AUTOSAR XML (schema 4-3-0)
package /CAN2/ISignalGroup
  10 x i signal group:
    CAN2_SG_FD2_C1000_0: i-signal=[CAN2_VCUVehAcclLimit, CAN2_VCUVehSpdlimit], system-signal-group=CAN2_SG_FD2_C1000_0
    CAN2_SG_CGW_FD2_C1000_0: i-signal=[CAN2_ACMODESta, CAN2_LBIBatWarn, CAN2_LBIPressIndi, CAN2_LBISensorFail, CAN2_LBIWheelPress, CAN2_LBIWheelTemp, CAN2_LBIWheelTmpIndi, CAN2_LBOBatWarn, CAN2_LBOPressIndi, CAN2_LBOSensorFail, CAN2_LBOWheelPress, CAN2_LBOWheelTemp, CAN2_LBOWheelTmpIndi, CAN2_LFBatWarn, CAN2_LFPressIndi, CAN2_LFSensorFail, CAN2_LFWheelPress, CAN2_LFWheelTemp, CAN2_LFWheelTmpIndi, CAN2_RBIBatWarn, CAN2_RBIPressIndi, CAN2_RBISensorFail, CAN2_RBIWheelPress, CAN2_RBIWheelTmpIndi, CAN2_RBOBatWarn, CAN2_RBOPressIndi, CAN2_RBOSensorFail, CAN2_RBOWheelPress, CAN2_RBOWheelTemp, CAN2_RBOWheelTmpIndi, CAN2_RFBatWarn, CAN2_RFPressIndi, CAN2_RFSensorFail, CAN2_RFWheelPress, CAN2_RFWheelTemp, CAN2_RFWheelTmpIndi, CAN2_THCM_Faultlv_Sta, CAN2_TPMSWarnIndi], system-signal-group=CAN2_SG_CGW_FD2_C1000_0
    CAN2_SG_FD2_C10_0: i-signal=[CAN2_ActDriveMode, CAN2_CeTraxSysReady, CAN2_CreeperSta, CAN2_EBrakeTorqLow, CAN2_EMotorOverSpd, CAN2_EMotorPerformance, CAN2_EMotorSpd, CAN2_EVECU1MSGCS, CAN2_EVECU1MSGCnt, CAN2_RecuperHighSta, CAN2_TUpASta, CAN2_VehActDriveDirect, CAN2_WheelSlipdet], system-signal-group=CAN2_SG_FD2_C10_0
    CAN2_SG_FD2_C200_0: i-signal=[CAN2_CACPresWarn, CAN2_FDC_VCU_VCUDRM_Sta, CAN2_SysPowerMode], system-signal-group=CAN2_SG_FD2_C200_0
    CAN2_SG_FD2_C500_0: i-signal=[CAN2_IGNKeySta, CAN2_VCU_VehicleSpd, CAN2_VSPFunc], system-signal-group=CAN2_SG_FD2_C500_0
    CAN2_SG_FD2_C50_0: i-signal=[CAN2_EVEHCMSGCS, CAN2_EVEHCMSGCnt, CAN2_EVSysRls, CAN2_ElecSysRdy, CAN2_ExtAccLimReq, CAN2_ExtDischgReq, CAN2_ExtDriveMReq, CAN2_ExtWorkshopMReq, CAN2_RecuperLimOrReq], system-signal-group=CAN2_SG_FD2_C50_0
    CAN2_SG_FD2_CE100_0: i-signal=[CAN2_FDC_BCM_BSD_Buzzer_Cmd, CAN2_FDC_BCM_Brake_Cmd, CAN2_FDC_BCM_CallBell_Cmd, CAN2_FDC_BCM_DVRSignalL_Cmd, CAN2_FDC_BCM_DVRSignalR_Cmd, CAN2_FDC_BCM_EmExitSW_Sta, CAN2_FDC_BCM_EmSV_Cmd, CAN2_FDC_BCM_FDCloseSV_Cmd, CAN2_FDC_BCM_FDOpenSV_Cmd, CAN2_FDC_BCM_FDoor_Sta, CAN2_FDC_BCM_FRoomLpSet_Sta, CAN2_FDC_BCM_HBeam_Cmd, CAN2_FDC_BCM_HazardSW_Sta, CAN2_FDC_BCM_HelpIND_Cmd, CAN2_FDC_BCM_InnerBuzzerMode_Sta, CAN2_FDC_BCM_InnerBuzzer_Cmd, CAN2_FDC_BCM_InnerCallBell_Cmd, CAN2_FDC_BCM_LBSDR_Cmd, CAN2_FDC_BCM_LBSDY_Cmd, CAN2_FDC_BCM_LBeam_Cmd, CAN2_FDC_BCM_LDRL_Cmd, CAN2_FDC_BCM_LTurnLp_Cmd, CAN2_FDC_BCM_LTurnSW_Sta, CAN2_FDC_BCM_MDCloseSV_Cmd, CAN2_FDC_BCM_MDOpenSV_Cmd, CAN2_FDC_BCM_MDoor_Sta, CAN2_FDC_BCM_MRoomLpSet_Sta, CAN2_FDC_BCM_OutDoorOpenSW_Sta, CAN2_FDC_BCM_PLamp_Cmd, CAN2_FDC_BCM_RBSDR_Cmd, CAN2_FDC_BCM_RBSDY_Cmd, CAN2_FDC_BCM_RDRL_Cmd, CAN2_FDC_BCM_RDoor_Sta, CAN2_FDC_BCM_RFLamp_Cmd, CAN2_FDC_BCM_RGear_Sta, CAN2_FDC_BCM_RRoomLpSet_Sta, CAN2_FDC_BCM_RTurnLp_Cmd, CAN2_FDC_BCM_RTurnSW_Sta, CAN2_FDC_BCM_RoomLpAmbSet_Sta, CAN2_FDC_BCM_RoomLpAmb_Cmd, CAN2_FDC_BCM_RoomLpSet_Sta, CAN2_FDC_BCM_SLTLp_Cmd, CAN2_FDC_BCM_SMKL_Cmd, CAN2_FDC_BCM_SMKR_Cmd, CAN2_FDC_BCM_SRTLp_Cmd, CAN2_FDC_BCM_STOPBALL_Cmd, CAN2_FDC_BCM_Stop_IND_Cmd, CAN2_FDC_BCM_TurnBuzzerEN_Sta, CAN2_FDC_BCM_TurnLpPattern_Sta, CAN2_FDC_BCM_Washer_Cmd, CAN2_FDC_BCM_WiperH_Cmd, CAN2_FDC_BCM_WiperL_Cmd], system-signal-group=CAN2_SG_FD2_CE100_0
    CAN2_SG_GW2_C100_0: i-signal=[CAN2_CACTempWarn, CAN2_DACStatus, CAN2_GearFlashInd, CAN2_LVBattLow, CAN2_PweLmtInd, CAN2_VCUWarnInd, CAN2_VCUnoPBInd], system-signal-group=CAN2_SG_GW2_C100_0
    CAN2_SG_CGW_GW2_C100_0: i-signal=[CAN2_ABSFullyOper, CAN2_ACTempSetSta, CAN2_ASC1KneelingInfo, CAN2_ASRBrakeCtrlAtc, CAN2_ASREngCtrlAtc, CAN2_AirPressureRC1, CAN2_B2THVRlySta, CAN2_B2VBI1BattType, CAN2_B2VBI1RateCap, CAN2_B2VBI1RateHVolt, CAN2_B2VBI1RatePower, CAN2_B2VChgMode, CAN2_B2VChgSta, CAN2_B2VDCChgConnSta, CAN2_B2VFaultCode, CAN2_B2VPChrgConnSta, CAN2_B2VSOC, CAN2_B2VSOH, CAN2_DCDC_En_Sta, CAN2_EBSAmWarnLampSta, CAN2_EBSBrakeSw, CAN2_EBSRedWarnLampSta, CAN2_ECASAWarmLampSta, CAN2_EHPS_ErrLv_Sta, CAN2_MCUFailGrade, CAN2_ParkBrakeSW, CAN2_TransReqGear, CAN2_VDCBrakeLightReq, CAN2_WhlSpeed_FL, CAN2_WhlSpeed_FR, CAN2_WhlSpeed_RL, CAN2_WhlSpeed_RR, CAN2_ZFR_CHASSIS_LiningWearFL_Sta, CAN2_ZFR_CHASSIS_LiningWearFR_Sta, CAN2_ZRR_CHASSIS_LiningWearRL_Sta, CAN2_ZRR_CHASSIS_LiningWearRR_Sta], system-signal-group=CAN2_SG_CGW_GW2_C100_0
    CAN2_SG_IVI_C100_0: i-signal=[CAN2_IVI_ACCoolTempSetdownReq_Cmd, CAN2_IVI_ACCoolTempSetupReq_Cmd, CAN2_IVI_ACFanSpdReq_Cmd, CAN2_IVI_ACHeatTempSetDownReq_Cmd, CAN2_IVI_ACHeatTempSetUPReq_Cmd, CAN2_IVI_ACMODEReq_Cmd, CAN2_IVI_ACOutCycleReq_Cmd, CAN2_IVI_ACPwrReq_Cmd, CAN2_IVI_ACRemoteReq_Cmd, CAN2_IVI_ACTempSet_Cmd], system-signal-group=CAN2_SG_IVI_C100_0
package /CAN2/Cluster
  can cluster CAN2: baudrate=500, can-fd-baudrate=2000
    can physical channel CAN2: comm-connectors=ConnCAN2
      frame CAN2_DiagFuncReqFT: id 0x7D0, frame-length=8, can-addressing-mode=STANDARD, can-fd-frame-support=false, can-frame-rx-behavior=CAN-20, can-frame-tx-behavior=CAN-20
        n pdu CAN2_DiagFuncReqFT: length=8
      frame CAN2_DiagPhysReqToCMS_L: id 0x6E2, frame-length=64, can-addressing-mode=STANDARD, can-fd-frame-support=true, can-frame-rx-behavior=CAN-FD, can-frame-tx-behavior=CAN-FD
        n pdu CAN2_DiagPhysReqToCMS_L: length=8
      frame CAN2_DiagPhysReqToCMS_R: id 0x6E3, frame-length=64, can-addressing-mode=STANDARD, can-fd-frame-support=true, can-frame-rx-behavior=CAN-FD, can-frame-tx-behavior=CAN-FD
        n pdu CAN2_DiagPhysReqToCMS_R: length=8
      frame CAN2_DiagPhysReqToIVI: id 0x6A0, frame-length=64, can-addressing-mode=STANDARD, can-fd-frame-support=true, can-frame-rx-behavior=CAN-FD, can-frame-tx-behavior=CAN-FD
        n pdu CAN2_DiagPhysReqToIVI: length=8
      frame CAN2_DiagPhysReqToIVI_F: id 0x6E0, frame-length=64, can-addressing-mode=STANDARD, can-fd-frame-support=true, can-frame-rx-behavior=CAN-FD, can-frame-tx-behavior=CAN-FD
        n pdu CAN2_DiagPhysReqToIVI_F: length=8
      frame CAN2_DiagPhysReqToIVI_M: id 0x6E1, frame-length=64, can-addressing-mode=STANDARD, can-fd-frame-support=true, can-frame-rx-behavior=CAN-FD, can-frame-tx-behavior=CAN-FD
        n pdu CAN2_DiagPhysReqToIVI_M: length=8
      frame CAN2_DiagPhysReqToMETER: id 0x682, frame-length=64, can-addressing-mode=STANDARD, can-fd-frame-support=true, can-frame-rx-behavior=CAN-FD, can-frame-tx-behavior=CAN-FD
        n pdu CAN2_DiagPhysReqToMETER: length=8
      frame CAN2_DiagRespFromCMS_L: id 0x662, frame-length=64, can-addressing-mode=STANDARD, can-fd-frame-support=true, can-frame-rx-behavior=CAN-FD, can-frame-tx-behavior=CAN-FD
        n pdu CAN2_DiagRespFromCMS_L: length=8
      frame CAN2_DiagRespFromCMS_R: id 0x663, frame-length=64, can-addressing-mode=STANDARD, can-fd-frame-support=true, can-frame-rx-behavior=CAN-FD, can-frame-tx-behavior=CAN-FD
        n pdu CAN2_DiagRespFromCMS_R: length=8
      frame CAN2_DiagRespFromIVI: id 0x620, frame-length=64, can-addressing-mode=STANDARD, can-fd-frame-support=true, can-frame-rx-behavior=CAN-FD, can-frame-tx-behavior=CAN-FD
        n pdu CAN2_DiagRespFromIVI: length=8
      frame CAN2_DiagRespFromIVI_F: id 0x660, frame-length=64, can-addressing-mode=STANDARD, can-fd-frame-support=true, can-frame-rx-behavior=CAN-FD, can-frame-tx-behavior=CAN-FD
        n pdu CAN2_DiagRespFromIVI_F: length=8
      frame CAN2_DiagRespFromIVI_M: id 0x661, frame-length=64, can-addressing-mode=STANDARD, can-fd-frame-support=true, can-frame-rx-behavior=CAN-FD, can-frame-tx-behavior=CAN-FD
        n pdu CAN2_DiagRespFromIVI_M: length=8
      frame CAN2_DiagRespFromMETER: id 0x602, frame-length=64, can-addressing-mode=STANDARD, can-fd-frame-support=true, can-frame-rx-behavior=CAN-FD, can-frame-tx-behavior=CAN-FD
        n pdu CAN2_DiagRespFromMETER: length=8
      frame CAN2_FD2_C1000_0: id 0x20E, frame-length=64, can-addressing-mode=STANDARD, can-fd-frame-support=true, can-frame-rx-behavior=CAN-FD, can-frame-tx-behavior=CAN-FD
        pdu CAN2_FD2_C1000_0: length=64, minimum-delay=0.0, transmission-mode-true-timing=cyclic-timing=time-period=1, unused-bit-pattern=0
          mapping CAN2_SG_FD2_C1000_0: i-signal-group=CAN2_SG_FD2_C1000_0, start-position=0, transfer-property=PENDING
          mapping CAN2_SG_CGW_FD2_C1000_0: i-signal-group=CAN2_SG_CGW_FD2_C1000_0, start-position=0, transfer-property=PENDING
          signal CAN2_ACMODESta: start 29, 2 bit, big-endian, i-signal-type=PRIMITIVE, init-value=constant-reference=Init_CAN2_ACMODESta, base-type=uint8, implementation-data-type=uint8, transfer-property=PENDING
          signal CAN2_LBIBatWarn: start 48, 1 bit, big-endian, i-signal-type=PRIMITIVE, init-value=constant-reference=Init_CAN2_LBIBatWarn, base-type=uint8, implementation-data-type=uint8, transfer-property=PENDING
          signal CAN2_LBIPressIndi: start 23, 2 bit, big-endian, i-signal-type=PRIMITIVE, init-value=constant-reference=Init_CAN2_LBIPressIndi, base-type=uint8, implementation-data-type=uint8, transfer-property=PENDING
          signal CAN2_LBISensorFail: start 24, 1 bit, big-endian, i-signal-type=PRIMITIVE, init-value=constant-reference=Init_CAN2_LBISensorFail, base-type=uint8, implementation-data-type=uint8, transfer-property=PENDING
          signal CAN2_LBIWheelPress: start 95, 8 bit, big-endian, i-signal-type=PRIMITIVE, init-value=constant-reference=Init_CAN2_LBIWheelPress, base-type=uint8, implementation-data-type=uint8, transfer-property=PENDING
          signal CAN2_LBIWheelTemp: start 39, 8 bit, big-endian, i-signal-type=PRIMITIVE, init-value=constant-reference=Init_CAN2_LBIWheelTemp, base-type=uint8, implementation-data-type=uint8, transfer-property=PENDING
          signal CAN2_LBIWheelTmpIndi: start 41, 1 bit, big-endian, i-signal-type=PRIMITIVE, init-value=constant-reference=Init_CAN2_LBIWheelTmpIndi, base-type=uint8, implementation-data-type=uint8, transfer-property=PENDING
          signal CAN2_LBOBatWarn: start 85, 1 bit, big-endian, i-signal-type=PRIMITIVE, init-value=constant-reference=Init_CAN2_LBOBatWarn, base-type=uint8, implementation-data-type=uint8, transfer-property=PENDING
          signal CAN2_LBOPressIndi: start 31, 2 bit, big-endian, i-signal-type=PRIMITIVE, init-value=constant-reference=Init_CAN2_LBOPressIndi, base-type=uint8, implementation-data-type=uint8, transfer-property=PENDING
          signal CAN2_LBOSensorFail: start 26, 1 bit, big-endian, i-signal-type=PRIMITIVE, init-value=constant-reference=Init_CAN2_LBOSensorFail, base-type=uint8, implementation-data-type=uint8, transfer-property=PENDING
          signal CAN2_LBOWheelPress: start 143, 8 bit, big-endian, i-signal-type=PRIMITIVE, init-value=constant-reference=Init_CAN2_LBOWheelPress, base-type=uint8, implementation-data-type=uint8, transfer-property=PENDING
          signal CAN2_LBOWheelTemp: start 135, 8 bit, big-endian, i-signal-type=PRIMITIVE, init-value=constant-reference=Init_CAN2_LBOWheelTemp, base-type=uint8, implementation-data-type=uint8, transfer-property=PENDING
          signal CAN2_LBOWheelTmpIndi: start 51, 1 bit, big-endian, i-signal-type=PRIMITIVE, init-value=constant-reference=Init_CAN2_LBOWheelTmpIndi, base-type=uint8, implementation-data-type=uint8, transfer-property=PENDING
          signal CAN2_LFBatWarn: start 46, 1 bit, big-endian, i-signal-type=PRIMITIVE, init-value=constant-reference=Init_CAN2_LFBatWarn, base-type=uint8, implementation-data-type=uint8, transfer-property=PENDING
          signal CAN2_LFPressIndi: start 19, 2 bit, big-endian, i-signal-type=PRIMITIVE, init-value=constant-reference=Init_CAN2_LFPressIndi, base-type=uint8, implementation-data-type=uint8, transfer-property=PENDING
          signal CAN2_LFSensorFail: start 43, 1 bit, big-endian, i-signal-type=PRIMITIVE, init-value=constant-reference=Init_CAN2_LFSensorFail, base-type=uint8, implementation-data-type=uint8, transfer-property=PENDING
          signal CAN2_LFWheelPress: start 71, 8 bit, big-endian, i-signal-type=PRIMITIVE, init-value=constant-reference=Init_CAN2_LFWheelPress, base-type=uint8, implementation-data-type=uint8, transfer-property=PENDING
          signal CAN2_LFWheelTemp: start 119, 8 bit, big-endian, i-signal-type=PRIMITIVE, init-value=constant-reference=Init_CAN2_LFWheelTemp, base-type=uint8, implementation-data-type=uint8, transfer-property=PENDING
          signal CAN2_LFWheelTmpIndi: start 55, 1 bit, big-endian, i-signal-type=PRIMITIVE, init-value=constant-reference=Init_CAN2_LFWheelTmpIndi, base-type=uint8, implementation-data-type=uint8, transfer-property=PENDING
          signal CAN2_RBIBatWarn: start 84, 1 bit, big-endian, i-signal-type=PRIMITIVE, init-value=constant-reference=Init_CAN2_RBIBatWarn, base-type=uint8, implementation-data-type=uint8, transfer-property=PENDING
          signal CAN2_RBIPressIndi: start 53, 2 bit, big-endian, i-signal-type=PRIMITIVE, init-value=constant-reference=Init_CAN2_RBIPressIndi, base-type=uint8, implementation-data-type=uint8, transfer-property=PENDING
          signal CAN2_RBISensorFail: start 25, 1 bit, big-endian, i-signal-type=PRIMITIVE, init-value=constant-reference=Init_CAN2_RBISensorFail, base-type=uint8, implementation-data-type=uint8, transfer-property=PENDING
          signal CAN2_RBIWheelPress: start 103, 8 bit, big-endian, i-signal-type=PRIMITIVE, init-value=constant-reference=Init_CAN2_RBIWheelPress, base-type=uint8, implementation-data-type=uint8, transfer-property=PENDING
          signal CAN2_RBIWheelTmpIndi: start 40, 1 bit, big-endian, i-signal-type=PRIMITIVE, init-value=constant-reference=Init_CAN2_RBIWheelTmpIndi, base-type=uint8, implementation-data-type=uint8, transfer-property=PENDING
          signal CAN2_RBOBatWarn: start 50, 1 bit, big-endian, i-signal-type=PRIMITIVE, init-value=constant-reference=Init_CAN2_RBOBatWarn, base-type=uint8, implementation-data-type=uint8, transfer-property=PENDING
          signal CAN2_RBOPressIndi: start 17, 2 bit, big-endian, i-signal-type=PRIMITIVE, init-value=constant-reference=Init_CAN2_RBOPressIndi, base-type=uint8, implementation-data-type=uint8, transfer-property=PENDING
          signal CAN2_RBOSensorFail: start 27, 1 bit, big-endian, i-signal-type=PRIMITIVE, init-value=constant-reference=Init_CAN2_RBOSensorFail, base-type=uint8, implementation-data-type=uint8, transfer-property=PENDING
          signal CAN2_RBOWheelPress: start 63, 8 bit, big-endian, i-signal-type=PRIMITIVE, init-value=constant-reference=Init_CAN2_RBOWheelPress, base-type=uint8, implementation-data-type=uint8, transfer-property=PENDING
          signal CAN2_RBOWheelTemp: start 127, 8 bit, big-endian, i-signal-type=PRIMITIVE, init-value=constant-reference=Init_CAN2_RBOWheelTemp, base-type=uint8, implementation-data-type=uint8, transfer-property=PENDING
          signal CAN2_RBOWheelTmpIndi: start 49, 1 bit, big-endian, i-signal-type=PRIMITIVE, init-value=constant-reference=Init_CAN2_RBOWheelTmpIndi, base-type=uint8, implementation-data-type=uint8, transfer-property=PENDING
          signal CAN2_RFBatWarn: start 47, 1 bit, big-endian, i-signal-type=PRIMITIVE, init-value=constant-reference=Init_CAN2_RFBatWarn, base-type=uint8, implementation-data-type=uint8, transfer-property=PENDING
          signal CAN2_RFPressIndi: start 21, 2 bit, big-endian, i-signal-type=PRIMITIVE, init-value=constant-reference=Init_CAN2_RFPressIndi, base-type=uint8, implementation-data-type=uint8, transfer-property=PENDING
          signal CAN2_RFSensorFail: start 42, 1 bit, big-endian, i-signal-type=PRIMITIVE, init-value=constant-reference=Init_CAN2_RFSensorFail, base-type=uint8, implementation-data-type=uint8, transfer-property=PENDING
          signal CAN2_RFWheelPress: start 79, 8 bit, big-endian, i-signal-type=PRIMITIVE, init-value=constant-reference=Init_CAN2_RFWheelPress, base-type=uint8, implementation-data-type=uint8, transfer-property=PENDING
          signal CAN2_RFWheelTemp: start 111, 8 bit, big-endian, i-signal-type=PRIMITIVE, init-value=constant-reference=Init_CAN2_RFWheelTemp, base-type=uint8, implementation-data-type=uint8, transfer-property=PENDING
          signal CAN2_RFWheelTmpIndi: start 54, 1 bit, big-endian, i-signal-type=PRIMITIVE, init-value=constant-reference=Init_CAN2_RFWheelTmpIndi, base-type=uint8, implementation-data-type=uint8, transfer-property=PENDING
          signal CAN2_THCM_Faultlv_Sta: start 45, 2 bit, big-endian, i-signal-type=PRIMITIVE, init-value=constant-reference=Init_CAN2_THCM_Faultlv_Sta, base-type=uint8, implementation-data-type=uint8, transfer-property=PENDING
          signal CAN2_TPMSWarnIndi: start 87, 2 bit, big-endian, i-signal-type=PRIMITIVE, init-value=constant-reference=Init_CAN2_TPMSWarnIndi, base-type=uint8, implementation-data-type=uint8, transfer-property=PENDING
          signal CAN2_VCUVehAcclLimit: start 15, 8 bit, big-endian, i-signal-type=PRIMITIVE, init-value=constant-reference=Init_CAN2_VCUVehAcclLimit, base-type=uint8, implementation-data-type=uint8, transfer-property=PENDING
          signal CAN2_VCUVehSpdlimit: start 7, 8 bit, big-endian, i-signal-type=PRIMITIVE, init-value=constant-reference=Init_CAN2_VCUVehSpdlimit, base-type=uint8, implementation-data-type=uint8, transfer-property=PENDING
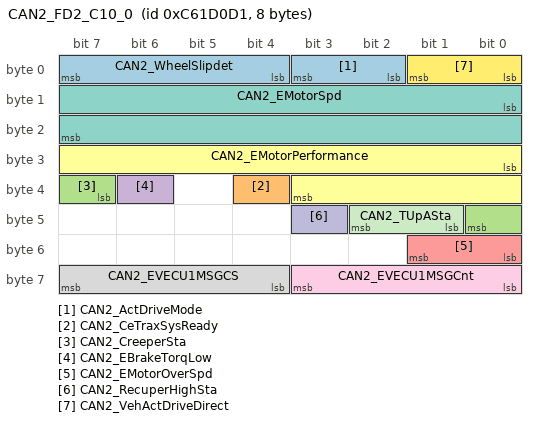
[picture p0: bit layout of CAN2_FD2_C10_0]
      frame CAN2_FD2_C10_0: id 0xC61D0D1, frame-length=8, can-addressing-mode=EXTENDED, can-fd-frame-support=false, can-frame-rx-behavior=CAN-20, can-frame-tx-behavior=CAN-20
        pdu CAN2_FD2_C10_0: length=8, minimum-delay=0.0, transmission-mode-true-timing=cyclic-timing=time-period=0.01, unused-bit-pattern=0
          mapping CAN2_SG_FD2_C10_0: i-signal-group=CAN2_SG_FD2_C10_0, start-position=0, transfer-property=PENDING
          signal CAN2_ActDriveMode: start 2, 2 bit, little-endian, i-signal-type=PRIMITIVE, init-value=constant-reference=Init_CAN2_ActDriveMode, base-type=uint8, implementation-data-type=uint8, transfer-property=PENDING
          signal CAN2_CeTraxSysReady: start 36, 1 bit, little-endian, i-signal-type=PRIMITIVE, init-value=constant-reference=Init_CAN2_CeTraxSysReady, base-type=uint8, implementation-data-type=uint8, transfer-property=PENDING
          signal CAN2_CreeperSta: start 39, 2 bit, little-endian, i-signal-type=PRIMITIVE, init-value=constant-reference=Init_CAN2_CreeperSta, base-type=uint8, implementation-data-type=uint8, transfer-property=PENDING
          signal CAN2_EBrakeTorqLow: start 38, 1 bit, little-endian, i-signal-type=PRIMITIVE, init-value=constant-reference=Init_CAN2_EBrakeTorqLow, base-type=uint8, implementation-data-type=uint8, transfer-property=PENDING
          signal CAN2_EMotorOverSpd: start 48, 2 bit, little-endian, i-signal-type=PRIMITIVE, init-value=constant-reference=Init_CAN2_EMotorOverSpd, base-type=uint8, implementation-data-type=uint8, transfer-property=PENDING
          signal CAN2_EMotorPerformance: start 24, 12 bit, little-endian, i-signal-type=PRIMITIVE, init-value=constant-reference=Init_CAN2_EMotorPerformance, base-type=uint16, implementation-data-type=uint16, transfer-property=PENDING
          signal CAN2_EMotorSpd: start 8, 16 bit, little-endian, i-signal-type=PRIMITIVE, init-value=constant-reference=Init_CAN2_EMotorSpd, base-type=uint16, implementation-data-type=uint16, transfer-property=PENDING
          signal CAN2_EVECU1MSGCS: start 60, 4 bit, little-endian, i-signal-type=PRIMITIVE, init-value=constant-reference=Init_CAN2_EVECU1MSGCS, base-type=uint8, implementation-data-type=uint8, transfer-property=PENDING
          signal CAN2_EVECU1MSGCnt: start 56, 4 bit, little-endian, i-signal-type=PRIMITIVE, init-value=constant-reference=Init_CAN2_EVECU1MSGCnt, base-type=uint8, implementation-data-type=uint8, transfer-property=PENDING
          signal CAN2_RecuperHighSta: start 43, 1 bit, little-endian, i-signal-type=PRIMITIVE, init-value=constant-reference=Init_CAN2_RecuperHighSta, base-type=uint8, implementation-data-type=uint8, transfer-property=PENDING
          signal CAN2_TUpASta: start 41, 2 bit, little-endian, i-signal-type=PRIMITIVE, init-value=constant-reference=Init_CAN2_TUpASta, base-type=uint8, implementation-data-type=uint8, transfer-property=PENDING
          signal CAN2_VehActDriveDirect: start 0, 2 bit, little-endian, i-signal-type=PRIMITIVE, init-value=constant-reference=Init_CAN2_VehActDriveDirect, base-type=uint8, implementation-data-type=uint8, transfer-property=PENDING
          signal CAN2_WheelSlipdet: start 4, 4 bit, little-endian, i-signal-type=PRIMITIVE, init-value=constant-reference=Init_CAN2_WheelSlipdet, base-type=uint8, implementation-data-type=uint8, transfer-property=PENDING
      frame CAN2_FD2_C200_0: id 0x20F, frame-length=32, can-addressing-mode=STANDARD, can-fd-frame-support=true, can-frame-rx-behavior=CAN-FD, can-frame-tx-behavior=CAN-FD
        pdu CAN2_FD2_C200_0: length=32, minimum-delay=0.0, transmission-mode-true-timing=cyclic-timing=time-period=0.2, unused-bit-pattern=0
          mapping CAN2_SG_FD2_C200_0: i-signal-group=CAN2_SG_FD2_C200_0, start-position=0, transfer-property=PENDING
          signal CAN2_CACPresWarn: start 5, 1 bit, big-endian, i-signal-type=PRIMITIVE, init-value=constant-reference=Init_CAN2_CACPresWarn, base-type=uint8, implementation-data-type=uint8, transfer-property=PENDING
          signal CAN2_FDC_VCU_VCUDRM_Sta: start 7, 2 bit, big-endian, i-signal-type=PRIMITIVE, init-value=constant-reference=Init_CAN2_FDC_VCU_VCUDRM_Sta, base-type=uint8, implementation-data-type=uint8, transfer-property=PENDING
          signal CAN2_SysPowerMode: start 4, 4 bit, big-endian, i-signal-type=PRIMITIVE, init-value=constant-reference=Init_CAN2_SysPowerMode, base-type=uint8, implementation-data-type=uint8, transfer-property=PENDING
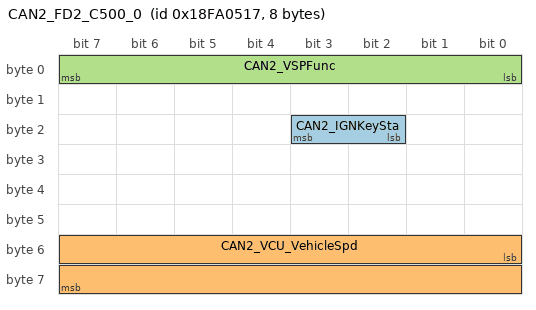
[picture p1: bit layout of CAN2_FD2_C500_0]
      frame CAN2_FD2_C500_0: id 0x18FA0517, frame-length=8, can-addressing-mode=EXTENDED, can-fd-frame-support=false, can-frame-rx-behavior=CAN-20, can-frame-tx-behavior=CAN-20
        pdu CAN2_FD2_C500_0: length=8, minimum-delay=0.0, transmission-mode-true-timing=cyclic-timing=time-period=0.5, unused-bit-pattern=0
          mapping CAN2_SG_FD2_C500_0: i-signal-group=CAN2_SG_FD2_C500_0, start-position=0, transfer-property=PENDING
          signal CAN2_IGNKeySta: start 18, 2 bit, little-endian, i-signal-type=PRIMITIVE, init-value=constant-reference=Init_CAN2_IGNKeySta, base-type=uint8, implementation-data-type=uint8, transfer-property=PENDING
          signal CAN2_VCU_VehicleSpd: start 48, 16 bit, little-endian, i-signal-type=PRIMITIVE, init-value=constant-reference=Init_CAN2_VCU_VehicleSpd, base-type=uint16, implementation-data-type=uint16, transfer-property=PENDING
          signal CAN2_VSPFunc: start 0, 8 bit, little-endian, i-signal-type=PRIMITIVE, init-value=constant-reference=Init_CAN2_VSPFunc, base-type=uint8, implementation-data-type=uint8, transfer-property=PENDING
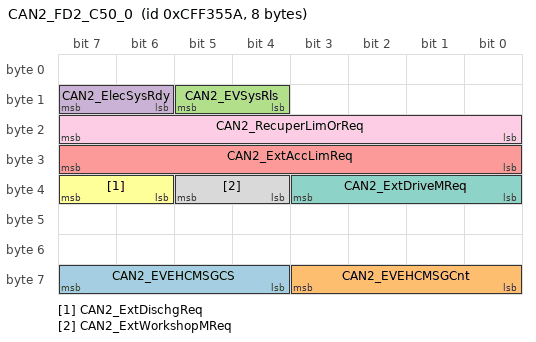
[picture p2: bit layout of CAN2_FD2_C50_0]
      frame CAN2_FD2_C50_0: id 0xCFF355A, frame-length=8, can-addressing-mode=EXTENDED, can-fd-frame-support=false, can-frame-rx-behavior=CAN-20, can-frame-tx-behavior=CAN-20
        pdu CAN2_FD2_C50_0: length=8, minimum-delay=0.0, transmission-mode-true-timing=cyclic-timing=time-period=0.05, unused-bit-pattern=0
          mapping CAN2_SG_FD2_C50_0: i-signal-group=CAN2_SG_FD2_C50_0, start-position=0, transfer-property=PENDING
          signal CAN2_EVEHCMSGCS: start 60, 4 bit, little-endian, i-signal-type=PRIMITIVE, init-value=constant-reference=Init_CAN2_EVEHCMSGCS, base-type=uint8, implementation-data-type=uint8, transfer-property=PENDING
          signal CAN2_EVEHCMSGCnt: start 56, 4 bit, little-endian, i-signal-type=PRIMITIVE, init-value=constant-reference=Init_CAN2_EVEHCMSGCnt, base-type=uint8, implementation-data-type=uint8, transfer-property=PENDING
          signal CAN2_EVSysRls: start 12, 2 bit, little-endian, i-signal-type=PRIMITIVE, init-value=constant-reference=Init_CAN2_EVSysRls, base-type=uint8, implementation-data-type=uint8, transfer-property=PENDING
          signal CAN2_ElecSysRdy: start 14, 2 bit, little-endian, i-signal-type=PRIMITIVE, init-value=constant-reference=Init_CAN2_ElecSysRdy, base-type=uint8, implementation-data-type=uint8, transfer-property=PENDING
          signal CAN2_ExtAccLimReq: start 24, 8 bit, little-endian, i-signal-type=PRIMITIVE, init-value=constant-reference=Init_CAN2_ExtAccLimReq, base-type=uint8, implementation-data-type=uint8, transfer-property=PENDING
          signal CAN2_ExtDischgReq: start 38, 2 bit, little-endian, i-signal-type=PRIMITIVE, init-value=constant-reference=Init_CAN2_ExtDischgReq, base-type=uint8, implementation-data-type=uint8, transfer-property=PENDING
          signal CAN2_ExtDriveMReq: start 32, 4 bit, little-endian, i-signal-type=PRIMITIVE, init-value=constant-reference=Init_CAN2_ExtDriveMReq, base-type=uint8, implementation-data-type=uint8, transfer-property=PENDING
          signal CAN2_ExtWorkshopMReq: start 36, 2 bit, little-endian, i-signal-type=PRIMITIVE, init-value=constant-reference=Init_CAN2_ExtWorkshopMReq, base-type=uint8, implementation-data-type=uint8, transfer-property=PENDING
          signal CAN2_RecuperLimOrReq: start 16, 8 bit, little-endian, i-signal-type=PRIMITIVE, init-value=constant-reference=Init_CAN2_RecuperLimOrReq, base-type=uint8, implementation-data-type=uint8, transfer-property=PENDING
      frame CAN2_FD2_CE100_0: id 0x209, frame-length=32, can-addressing-mode=STANDARD, can-fd-frame-support=true, can-frame-rx-behavior=CAN-FD, can-frame-tx-behavior=CAN-FD
        pdu CAN2_FD2_CE100_0: length=32, minimum-delay=0.0, transmission-mode-true-timing={cyclic-timing=time-period=0.1, event-controlled-timing={number-of-repetitions=0, repetition-period=0}}, unused-bit-pattern=0
          mapping CAN2_SG_FD2_CE100_0: i-signal-group=CAN2_SG_FD2_CE100_0, start-position=0, transfer-property=TRIGGERED-ON-CHANGE
          signal CAN2_FDC_BCM_BSD_Buzzer_Cmd: start 39, 1 bit, big-endian, i-signal-type=PRIMITIVE, init-value=constant-reference=Init_CAN2_FDC_BCM_BSD_Buzzer_Cmd, base-type=uint8, implementation-data-type=uint8, transfer-property=TRIGGERED-ON-CHANGE
          signal CAN2_FDC_BCM_Brake_Cmd: start 30, 1 bit, big-endian, i-signal-type=PRIMITIVE, init-value=constant-reference=Init_CAN2_FDC_BCM_Brake_Cmd, base-type=uint8, implementation-data-type=uint8, transfer-property=TRIGGERED-ON-CHANGE
          signal CAN2_FDC_BCM_CallBell_Cmd: start 20, 1 bit, big-endian, i-signal-type=PRIMITIVE, init-value=constant-reference=Init_CAN2_FDC_BCM_CallBell_Cmd, base-type=uint8, implementation-data-type=uint8, transfer-property=TRIGGERED-ON-CHANGE
          signal CAN2_FDC_BCM_DVRSignalL_Cmd: start 52, 1 bit, big-endian, i-signal-type=PRIMITIVE, init-value=constant-reference=Init_CAN2_FDC_BCM_DVRSignalL_Cmd, base-type=uint8, implementation-data-type=uint8, transfer-property=PENDING
          signal CAN2_FDC_BCM_DVRSignalR_Cmd: start 51, 1 bit, big-endian, i-signal-type=PRIMITIVE, init-value=constant-reference=Init_CAN2_FDC_BCM_DVRSignalR_Cmd, base-type=uint8, implementation-data-type=uint8, transfer-property=PENDING
          signal CAN2_FDC_BCM_EmExitSW_Sta: start 9, 1 bit, big-endian, i-signal-type=PRIMITIVE, init-value=constant-reference=Init_CAN2_FDC_BCM_EmExitSW_Sta, base-type=uint8, implementation-data-type=uint8, transfer-property=TRIGGERED-ON-CHANGE
          signal CAN2_FDC_BCM_EmSV_Cmd: start 6, 1 bit, big-endian, i-signal-type=PRIMITIVE, init-value=constant-reference=Init_CAN2_FDC_BCM_EmSV_Cmd, base-type=uint8, implementation-data-type=uint8, transfer-property=TRIGGERED-ON-CHANGE
          signal CAN2_FDC_BCM_FDCloseSV_Cmd: start 3, 1 bit, big-endian, i-signal-type=PRIMITIVE, init-value=constant-reference=Init_CAN2_FDC_BCM_FDCloseSV_Cmd, base-type=uint8, implementation-data-type=uint8, transfer-property=TRIGGERED-ON-CHANGE
          signal CAN2_FDC_BCM_FDOpenSV_Cmd: start 2, 1 bit, big-endian, i-signal-type=PRIMITIVE, init-value=constant-reference=Init_CAN2_FDC_BCM_FDOpenSV_Cmd, base-type=uint8, implementation-data-type=uint8, transfer-property=TRIGGERED-ON-CHANGE
          signal CAN2_FDC_BCM_FDoor_Sta: start 45, 1 bit, big-endian, i-signal-type=PRIMITIVE, init-value=constant-reference=Init_CAN2_FDC_BCM_FDoor_Sta, base-type=uint8, implementation-data-type=uint8, transfer-property=TRIGGERED-ON-CHANGE
          signal CAN2_FDC_BCM_FRoomLpSet_Sta: start 79, 7 bit, big-endian, i-signal-type=PRIMITIVE, init-value=constant-reference=Init_CAN2_FDC_BCM_FRoomLpSet_Sta, base-type=uint8, implementation-data-type=uint8, transfer-property=TRIGGERED-ON-CHANGE
          signal CAN2_FDC_BCM_HBeam_Cmd: start 40, 1 bit, big-endian, i-signal-type=PRIMITIVE, init-value=constant-reference=Init_CAN2_FDC_BCM_HBeam_Cmd, base-type=uint8, implementation-data-type=uint8, transfer-property=TRIGGERED-ON-CHANGE
          signal CAN2_FDC_BCM_HazardSW_Sta: start 15, 1 bit, big-endian, i-signal-type=PRIMITIVE, init-value=constant-reference=Init_CAN2_FDC_BCM_HazardSW_Sta, base-type=uint8, implementation-data-type=uint8, transfer-property=TRIGGERED-ON-CHANGE
          signal CAN2_FDC_BCM_HelpIND_Cmd: start 12, 1 bit, big-endian, i-signal-type=PRIMITIVE, init-value=constant-reference=Init_CAN2_FDC_BCM_HelpIND_Cmd, base-type=uint8, implementation-data-type=uint8, transfer-property=TRIGGERED-ON-CHANGE
          signal CAN2_FDC_BCM_InnerBuzzerMode_Sta: start 23, 3 bit, big-endian, i-signal-type=PRIMITIVE, init-value=constant-reference=Init_CAN2_FDC_BCM_InnerBuzzerMode_Sta, base-type=uint8, implementation-data-type=uint8, transfer-property=TRIGGERED-ON-CHANGE
          signal CAN2_FDC_BCM_InnerBuzzer_Cmd: start 8, 1 bit, big-endian, i-signal-type=PRIMITIVE, init-value=constant-reference=Init_CAN2_FDC_BCM_InnerBuzzer_Cmd, base-type=uint8, implementation-data-type=uint8, transfer-property=TRIGGERED-ON-CHANGE
          signal CAN2_FDC_BCM_InnerCallBell_Cmd: start 19, 1 bit, big-endian, i-signal-type=PRIMITIVE, init-value=constant-reference=Init_CAN2_FDC_BCM_InnerCallBell_Cmd, base-type=uint8, implementation-data-type=uint8, transfer-property=TRIGGERED-ON-CHANGE
          signal CAN2_FDC_BCM_LBSDR_Cmd: start 35, 1 bit, big-endian, i-signal-type=PRIMITIVE, init-value=constant-reference=Init_CAN2_FDC_BCM_LBSDR_Cmd, base-type=uint8, implementation-data-type=uint8, transfer-property=TRIGGERED-ON-CHANGE
          signal CAN2_FDC_BCM_LBSDY_Cmd: start 36, 1 bit, big-endian, i-signal-type=PRIMITIVE, init-value=constant-reference=Init_CAN2_FDC_BCM_LBSDY_Cmd, base-type=uint8, implementation-data-type=uint8, transfer-property=TRIGGERED-ON-CHANGE
          signal CAN2_FDC_BCM_LBeam_Cmd: start 55, 1 bit, big-endian, i-signal-type=PRIMITIVE, init-value=constant-reference=Init_CAN2_FDC_BCM_LBeam_Cmd, base-type=uint8, implementation-data-type=uint8, transfer-property=TRIGGERED-ON-CHANGE
          signal CAN2_FDC_BCM_LDRL_Cmd: start 42, 1 bit, big-endian, i-signal-type=PRIMITIVE, init-value=constant-reference=Init_CAN2_FDC_BCM_LDRL_Cmd, base-type=uint8, implementation-data-type=uint8, transfer-property=TRIGGERED-ON-CHANGE
          signal CAN2_FDC_BCM_LTurnLp_Cmd: start 54, 1 bit, big-endian, i-signal-type=PRIMITIVE, init-value=constant-reference=Init_CAN2_FDC_BCM_LTurnLp_Cmd, base-type=uint8, implementation-data-type=uint8, transfer-property=PENDING
          signal CAN2_FDC_BCM_LTurnSW_Sta: start 13, 1 bit, big-endian, i-signal-type=PRIMITIVE, init-value=constant-reference=Init_CAN2_FDC_BCM_LTurnSW_Sta, base-type=uint8, implementation-data-type=uint8, transfer-property=TRIGGERED-ON-CHANGE
          signal CAN2_FDC_BCM_MDCloseSV_Cmd: start 5, 1 bit, big-endian, i-signal-type=PRIMITIVE, init-value=constant-reference=Init_CAN2_FDC_BCM_MDCloseSV_Cmd, base-type=uint8, implementation-data-type=uint8, transfer-property=TRIGGERED-ON-CHANGE
          signal CAN2_FDC_BCM_MDOpenSV_Cmd: start 4, 1 bit, big-endian, i-signal-type=PRIMITIVE, init-value=constant-reference=Init_CAN2_FDC_BCM_MDOpenSV_Cmd, base-type=uint8, implementation-data-type=uint8, transfer-property=TRIGGERED-ON-CHANGE
          signal CAN2_FDC_BCM_MDoor_Sta: start 44, 1 bit, big-endian, i-signal-type=PRIMITIVE, init-value=constant-reference=Init_CAN2_FDC_BCM_MDoor_Sta, base-type=uint8, implementation-data-type=uint8, transfer-property=TRIGGERED-ON-CHANGE
          signal CAN2_FDC_BCM_MRoomLpSet_Sta: start 63, 7 bit, big-endian, i-signal-type=PRIMITIVE, init-value=constant-reference=Init_CAN2_FDC_BCM_MRoomLpSet_Sta, base-type=uint8, implementation-data-type=uint8, transfer-property=PENDING
          signal CAN2_FDC_BCM_OutDoorOpenSW_Sta: start 1, 2 bit, big-endian, i-signal-type=PRIMITIVE, init-value=constant-reference=Init_CAN2_FDC_BCM_OutDoorOpenSW_Sta, base-type=uint8, implementation-data-type=uint8, transfer-property=TRIGGERED-ON-CHANGE
          signal CAN2_FDC_BCM_PLamp_Cmd: start 41, 1 bit, big-endian, i-signal-type=PRIMITIVE, init-value=constant-reference=Init_CAN2_FDC_BCM_PLamp_Cmd, base-type=uint8, implementation-data-type=uint8, transfer-property=TRIGGERED-ON-CHANGE
          signal CAN2_FDC_BCM_RBSDR_Cmd: start 37, 1 bit, big-endian, i-signal-type=PRIMITIVE, init-value=constant-reference=Init_CAN2_FDC_BCM_RBSDR_Cmd, base-type=uint8, implementation-data-type=uint8, transfer-property=TRIGGERED-ON-CHANGE
          signal CAN2_FDC_BCM_RBSDY_Cmd: start 38, 1 bit, big-endian, i-signal-type=PRIMITIVE, init-value=constant-reference=Init_CAN2_FDC_BCM_RBSDY_Cmd, base-type=uint8, implementation-data-type=uint8, transfer-property=TRIGGERED-ON-CHANGE
          signal CAN2_FDC_BCM_RDRL_Cmd: start 43, 1 bit, big-endian, i-signal-type=PRIMITIVE, init-value=constant-reference=Init_CAN2_FDC_BCM_RDRL_Cmd, base-type=uint8, implementation-data-type=uint8, transfer-property=TRIGGERED-ON-CHANGE
          signal CAN2_FDC_BCM_RDoor_Sta: start 46, 1 bit, big-endian, i-signal-type=PRIMITIVE, init-value=constant-reference=Init_CAN2_FDC_BCM_RDoor_Sta, base-type=uint8, implementation-data-type=uint8, transfer-property=TRIGGERED-ON-CHANGE
          signal CAN2_FDC_BCM_RFLamp_Cmd: start 31, 1 bit, big-endian, i-signal-type=PRIMITIVE, init-value=constant-reference=Init_CAN2_FDC_BCM_RFLamp_Cmd, base-type=uint8, implementation-data-type=uint8, transfer-property=TRIGGERED-ON-CHANGE
          signal CAN2_FDC_BCM_RGear_Sta: start 47, 1 bit, big-endian, i-signal-type=PRIMITIVE, init-value=constant-reference=Init_CAN2_FDC_BCM_RGear_Sta, base-type=uint8, implementation-data-type=uint8, transfer-property=TRIGGERED-ON-CHANGE
          signal CAN2_FDC_BCM_RRoomLpSet_Sta: start 71, 7 bit, big-endian, i-signal-type=PRIMITIVE, init-value=constant-reference=Init_CAN2_FDC_BCM_RRoomLpSet_Sta, base-type=uint8, implementation-data-type=uint8, transfer-property=TRIGGERED-ON-CHANGE
          signal CAN2_FDC_BCM_RTurnLp_Cmd: start 53, 1 bit, big-endian, i-signal-type=PRIMITIVE, init-value=constant-reference=Init_CAN2_FDC_BCM_RTurnLp_Cmd, base-type=uint8, implementation-data-type=uint8, transfer-property=PENDING
          signal CAN2_FDC_BCM_RTurnSW_Sta: start 14, 1 bit, big-endian, i-signal-type=PRIMITIVE, init-value=constant-reference=Init_CAN2_FDC_BCM_RTurnSW_Sta, base-type=uint8, implementation-data-type=uint8, transfer-property=TRIGGERED-ON-CHANGE
          signal CAN2_FDC_BCM_RoomLpAmbSet_Sta: start 10, 1 bit, big-endian, i-signal-type=PRIMITIVE, init-value=constant-reference=Init_CAN2_FDC_BCM_RoomLpAmbSet_Sta, base-type=uint8, implementation-data-type=uint8, transfer-property=TRIGGERED-ON-CHANGE
          signal CAN2_FDC_BCM_RoomLpAmb_Cmd: start 25, 1 bit, big-endian, i-signal-type=PRIMITIVE, init-value=constant-reference=Init_CAN2_FDC_BCM_RoomLpAmb_Cmd, base-type=uint8, implementation-data-type=uint8, transfer-property=TRIGGERED-ON-CHANGE
          signal CAN2_FDC_BCM_RoomLpSet_Sta: start 11, 1 bit, big-endian, i-signal-type=PRIMITIVE, init-value=constant-reference=Init_CAN2_FDC_BCM_RoomLpSet_Sta, base-type=uint8, implementation-data-type=uint8, transfer-property=TRIGGERED-ON-CHANGE
          signal CAN2_FDC_BCM_SLTLp_Cmd: start 29, 1 bit, big-endian, i-signal-type=PRIMITIVE, init-value=constant-reference=Init_CAN2_FDC_BCM_SLTLp_Cmd, base-type=uint8, implementation-data-type=uint8, transfer-property=TRIGGERED-ON-CHANGE
          signal CAN2_FDC_BCM_SMKL_Cmd: start 26, 1 bit, big-endian, i-signal-type=PRIMITIVE, init-value=constant-reference=Init_CAN2_FDC_BCM_SMKL_Cmd, base-type=uint8, implementation-data-type=uint8, transfer-property=TRIGGERED-ON-CHANGE
          signal CAN2_FDC_BCM_SMKR_Cmd: start 27, 1 bit, big-endian, i-signal-type=PRIMITIVE, init-value=constant-reference=Init_CAN2_FDC_BCM_SMKR_Cmd, base-type=uint8, implementation-data-type=uint8, transfer-property=TRIGGERED-ON-CHANGE
          signal CAN2_FDC_BCM_SRTLp_Cmd: start 28, 1 bit, big-endian, i-signal-type=PRIMITIVE, init-value=constant-reference=Init_CAN2_FDC_BCM_SRTLp_Cmd, base-type=uint8, implementation-data-type=uint8, transfer-property=TRIGGERED-ON-CHANGE
          signal CAN2_FDC_BCM_STOPBALL_Cmd: start 18, 1 bit, big-endian, i-signal-type=PRIMITIVE, init-value=constant-reference=Init_CAN2_FDC_BCM_STOPBALL_Cmd, base-type=uint8, implementation-data-type=uint8, transfer-property=TRIGGERED-ON-CHANGE
          signal CAN2_FDC_BCM_Stop_IND_Cmd: start 24, 1 bit, big-endian, i-signal-type=PRIMITIVE, init-value=constant-reference=Init_CAN2_FDC_BCM_Stop_IND_Cmd, base-type=uint8, implementation-data-type=uint8, transfer-property=TRIGGERED-ON-CHANGE
          signal CAN2_FDC_BCM_TurnBuzzerEN_Sta: start 7, 1 bit, big-endian, i-signal-type=PRIMITIVE, init-value=constant-reference=Init_CAN2_FDC_BCM_TurnBuzzerEN_Sta, base-type=uint8, implementation-data-type=uint8, transfer-property=TRIGGERED-ON-CHANGE
          signal CAN2_FDC_BCM_TurnLpPattern_Sta: start 17, 2 bit, big-endian, i-signal-type=PRIMITIVE, init-value=constant-reference=Init_CAN2_FDC_BCM_TurnLpPattern_Sta, base-type=uint8, implementation-data-type=uint8, transfer-property=TRIGGERED-ON-CHANGE
          signal CAN2_FDC_BCM_Washer_Cmd: start 34, 1 bit, big-endian, i-signal-type=PRIMITIVE, init-value=constant-reference=Init_CAN2_FDC_BCM_Washer_Cmd, base-type=uint8, implementation-data-type=uint8, transfer-property=TRIGGERED-ON-CHANGE
          signal CAN2_FDC_BCM_WiperH_Cmd: start 32, 1 bit, big-endian, i-signal-type=PRIMITIVE, init-value=constant-reference=Init_CAN2_FDC_BCM_WiperH_Cmd, base-type=uint8, implementation-data-type=uint8, transfer-property=TRIGGERED-ON-CHANGE
          signal CAN2_FDC_BCM_WiperL_Cmd: start 33, 1 bit, big-endian, i-signal-type=PRIMITIVE, init-value=constant-reference=Init_CAN2_FDC_BCM_WiperL_Cmd, base-type=uint8, implementation-data-type=uint8, transfer-property=TRIGGERED-ON-CHANGE
      frame CAN2_GW2_C100_0: id 0x20B, frame-length=32, can-addressing-mode=STANDARD, can-fd-frame-support=true, can-frame-rx-behavior=CAN-FD, can-frame-tx-behavior=CAN-FD
        pdu CAN2_GW2_C100_0: length=32, minimum-delay=0.0, transmission-mode-true-timing=cyclic-timing=time-period=0.1, unused-bit-pattern=0
          mapping CAN2_SG_GW2_C100_0: i-signal-group=CAN2_SG_GW2_C100_0, start-position=0, transfer-property=PENDING
          mapping CAN2_SG_CGW_GW2_C100_0: i-signal-group=CAN2_SG_CGW_GW2_C100_0, start-position=0, transfer-property=PENDING
          signal CAN2_ABSFullyOper: start 109, 2 bit, big-endian, i-signal-type=PRIMITIVE, init-value=constant-reference=Init_CAN2_ABSFullyOper, base-type=uint8, implementation-data-type=uint8, transfer-property=PENDING
          signal CAN2_ACTempSetSta: start 79, 8 bit, big-endian, i-signal-type=PRIMITIVE, init-value=constant-reference=Init_CAN2_ACTempSetSta, base-type=uint8, implementation-data-type=uint8, transfer-property=PENDING
          signal CAN2_ASC1KneelingInfo: start 183, 4 bit, big-endian, i-signal-type=PRIMITIVE, init-value=constant-reference=Init_CAN2_ASC1KneelingInfo, base-type=uint8, implementation-data-type=uint8, transfer-property=PENDING
          signal CAN2_ASRBrakeCtrlAtc: start 65, 2 bit, big-endian, i-signal-type=PRIMITIVE, init-value=constant-reference=Init_CAN2_ASRBrakeCtrlAtc, base-type=uint8, implementation-data-type=uint8, transfer-property=PENDING
          signal CAN2_ASREngCtrlAtc: start 111, 2 bit, big-endian, i-signal-type=PRIMITIVE, init-value=constant-reference=Init_CAN2_ASREngCtrlAtc, base-type=uint8, implementation-data-type=uint8, transfer-property=PENDING
          signal CAN2_AirPressureRC1: start 207, 8 bit, big-endian, i-signal-type=PRIMITIVE, init-value=constant-reference=Init_CAN2_AirPressureRC1, base-type=uint8, implementation-data-type=uint8, transfer-property=PENDING
          signal CAN2_B2THVRlySta: start 11, 2 bit, big-endian, i-signal-type=PRIMITIVE, init-value=constant-reference=Init_CAN2_B2THVRlySta, base-type=uint8, implementation-data-type=uint8, transfer-property=PENDING
          signal CAN2_B2VBI1BattType: start 15, 4 bit, big-endian, i-signal-type=PRIMITIVE, init-value=constant-reference=Init_CAN2_B2VBI1BattType, base-type=uint8, implementation-data-type=uint8, transfer-property=PENDING
          signal CAN2_B2VBI1RateCap: start 23, 16 bit, big-endian, i-signal-type=PRIMITIVE, init-value=constant-reference=Init_CAN2_B2VBI1RateCap, base-type=uint16, implementation-data-type=uint16, transfer-property=PENDING
          signal CAN2_B2VBI1RateHVolt: start 39, 16 bit, big-endian, i-signal-type=PRIMITIVE, init-value=constant-reference=Init_CAN2_B2VBI1RateHVolt, base-type=uint16, implementation-data-type=uint16, transfer-property=PENDING
          signal CAN2_B2VBI1RatePower: start 55, 16 bit, big-endian, i-signal-type=PRIMITIVE, init-value=constant-reference=Init_CAN2_B2VBI1RatePower, base-type=uint16, implementation-data-type=uint16, transfer-property=PENDING
          signal CAN2_B2VChgMode: start 9, 2 bit, big-endian, i-signal-type=PRIMITIVE, init-value=constant-reference=Init_CAN2_B2VChgMode, base-type=uint8, implementation-data-type=uint8, transfer-property=PENDING
          signal CAN2_B2VChgSta: start 71, 2 bit, big-endian, i-signal-type=PRIMITIVE, init-value=constant-reference=Init_CAN2_B2VChgSta, base-type=uint8, implementation-data-type=uint8, transfer-property=PENDING
          signal CAN2_B2VDCChgConnSta: start 69, 2 bit, big-endian, i-signal-type=PRIMITIVE, init-value=constant-reference=Init_CAN2_B2VDCChgConnSta, base-type=uint8, implementation-data-type=uint8, transfer-property=PENDING
          signal CAN2_B2VFaultCode: start 95, 8 bit, big-endian, i-signal-type=PRIMITIVE, init-value=constant-reference=Init_CAN2_B2VFaultCode, base-type=uint8, implementation-data-type=uint8, transfer-property=PENDING
          signal CAN2_B2VPChrgConnSta: start 67, 1 bit, big-endian, i-signal-type=PRIMITIVE, init-value=constant-reference=Init_CAN2_B2VPChrgConnSta, base-type=uint8, implementation-data-type=uint8, transfer-property=PENDING
          signal CAN2_B2VSOC: start 87, 8 bit, big-endian, i-signal-type=PRIMITIVE, init-value=constant-reference=Init_CAN2_B2VSOC, base-type=uint8, implementation-data-type=uint8, transfer-property=PENDING
          signal CAN2_B2VSOH: start 7, 8 bit, big-endian, i-signal-type=PRIMITIVE, init-value=constant-reference=Init_CAN2_B2VSOH, base-type=uint8, implementation-data-type=uint8, transfer-property=PENDING
          signal CAN2_CACTempWarn: start 177, 1 bit, big-endian, i-signal-type=PRIMITIVE, init-value=constant-reference=Init_CAN2_CACTempWarn, base-type=uint8, implementation-data-type=uint8, transfer-property=PENDING
          signal CAN2_DACStatus: start 231, 2 bit, big-endian, i-signal-type=PRIMITIVE, init-value=constant-reference=Init_CAN2_DACStatus, base-type=uint8, implementation-data-type=uint8, transfer-property=PENDING
          signal CAN2_DCDC_En_Sta: start 213, 2 bit, big-endian, i-signal-type=PRIMITIVE, init-value=constant-reference=Init_CAN2_DCDC_En_Sta, base-type=uint8, implementation-data-type=uint8, transfer-property=PENDING
          signal CAN2_EBSAmWarnLampSta: start 107, 2 bit, big-endian, i-signal-type=PRIMITIVE, init-value=constant-reference=Init_CAN2_EBSAmWarnLampSta, base-type=uint8, implementation-data-type=uint8, transfer-property=PENDING
          signal CAN2_EBSBrakeSw: start 215, 2 bit, big-endian, i-signal-type=PRIMITIVE, init-value=constant-reference=Init_CAN2_EBSBrakeSw, base-type=uint8, implementation-data-type=uint8, transfer-property=PENDING
          signal CAN2_EBSRedWarnLampSta: start 105, 2 bit, big-endian, i-signal-type=PRIMITIVE, init-value=constant-reference=Init_CAN2_EBSRedWarnLampSta, base-type=uint8, implementation-data-type=uint8, transfer-property=PENDING
          signal CAN2_ECASAWarmLampSta: start 179, 2 bit, big-endian, i-signal-type=PRIMITIVE, init-value=constant-reference=Init_CAN2_ECASAWarmLampSta, base-type=uint8, implementation-data-type=uint8, transfer-property=PENDING
          signal CAN2_EHPS_ErrLv_Sta: start 191, 3 bit, big-endian, i-signal-type=PRIMITIVE, init-value=constant-reference=Init_CAN2_EHPS_ErrLv_Sta, base-type=uint8, implementation-data-type=uint8, transfer-property=PENDING
          signal CAN2_GearFlashInd: start 66, 1 bit, big-endian, i-signal-type=PRIMITIVE, init-value=constant-reference=Init_CAN2_GearFlashInd, base-type=uint8, implementation-data-type=uint8, transfer-property=PENDING
          signal CAN2_LVBattLow: start 223, 2 bit, big-endian, i-signal-type=PRIMITIVE, init-value=constant-reference=Init_CAN2_LVBattLow, base-type=uint8, implementation-data-type=uint8, transfer-property=PENDING
          signal CAN2_MCUFailGrade: start 188, 4 bit, big-endian, i-signal-type=PRIMITIVE, init-value=constant-reference=Init_CAN2_MCUFailGrade, base-type=uint8, implementation-data-type=uint8, transfer-property=PENDING
          signal CAN2_ParkBrakeSW: start 211, 2 bit, big-endian, i-signal-type=PRIMITIVE, init-value=constant-reference=Init_CAN2_ParkBrakeSW, base-type=uint8, implementation-data-type=uint8, transfer-property=PENDING
          signal CAN2_PweLmtInd: start 221, 1 bit, big-endian, i-signal-type=PRIMITIVE, init-value=constant-reference=Init_CAN2_PweLmtInd, base-type=uint8, implementation-data-type=uint8, transfer-property=PENDING
          signal CAN2_TransReqGear: start 103, 8 bit, big-endian, i-signal-type=PRIMITIVE, init-value=constant-reference=Init_CAN2_TransReqGear, base-type=uint8, implementation-data-type=uint8, transfer-property=PENDING
          signal CAN2_VCUWarnInd: start 220, 3 bit, big-endian, i-signal-type=PRIMITIVE, init-value=constant-reference=Init_CAN2_VCUWarnInd, base-type=uint8, implementation-data-type=uint8, transfer-property=PENDING
          signal CAN2_VCUnoPBInd: start 217, 1 bit, big-endian, i-signal-type=PRIMITIVE, init-value=constant-reference=Init_CAN2_VCUnoPBInd, base-type=uint8, implementation-data-type=uint8, transfer-property=PENDING
          signal CAN2_VDCBrakeLightReq: start 229, 2 bit, big-endian, i-signal-type=PRIMITIVE, init-value=constant-reference=Init_CAN2_VDCBrakeLightReq, base-type=uint8, implementation-data-type=uint8, transfer-property=PENDING
          signal CAN2_WhlSpeed_FL: start 119, 16 bit, big-endian, i-signal-type=PRIMITIVE, init-value=constant-reference=Init_CAN2_WhlSpeed_FL, base-type=uint16, implementation-data-type=uint16, transfer-property=PENDING
          signal CAN2_WhlSpeed_FR: start 135, 16 bit, big-endian, i-signal-type=PRIMITIVE, init-value=constant-reference=Init_CAN2_WhlSpeed_FR, base-type=uint16, implementation-data-type=uint16, transfer-property=PENDING
          signal CAN2_WhlSpeed_RL: start 151, 16 bit, big-endian, i-signal-type=PRIMITIVE, init-value=constant-reference=Init_CAN2_WhlSpeed_RL, base-type=uint16, implementation-data-type=uint16, transfer-property=PENDING
          signal CAN2_WhlSpeed_RR: start 167, 16 bit, big-endian, i-signal-type=PRIMITIVE, init-value=constant-reference=Init_CAN2_WhlSpeed_RR, base-type=uint16, implementation-data-type=uint16, transfer-property=PENDING
          signal CAN2_ZFR_CHASSIS_LiningWearFL_Sta: start 176, 1 bit, big-endian, i-signal-type=PRIMITIVE, init-value=constant-reference=Init_CAN2_ZFR_CHASSIS_LiningWearFL_Sta, base-type=uint8, implementation-data-type=uint8, transfer-property=PENDING
          signal CAN2_ZFR_CHASSIS_LiningWearFR_Sta: start 184, 1 bit, big-endian, i-signal-type=PRIMITIVE, init-value=constant-reference=Init_CAN2_ZFR_CHASSIS_LiningWearFR_Sta, base-type=uint8, implementation-data-type=uint8, transfer-property=PENDING
          signal CAN2_ZRR_CHASSIS_LiningWearRL_Sta: start 209, 1 bit, big-endian, i-signal-type=PRIMITIVE, init-value=constant-reference=Init_CAN2_ZRR_CHASSIS_LiningWearRL_Sta, base-type=uint8, implementation-data-type=uint8, transfer-property=PENDING
          signal CAN2_ZRR_CHASSIS_LiningWearRR_Sta: start 208, 1 bit, big-endian, i-signal-type=PRIMITIVE, init-value=constant-reference=Init_CAN2_ZRR_CHASSIS_LiningWearRR_Sta, base-type=uint8, implementation-data-type=uint8, transfer-property=PENDING
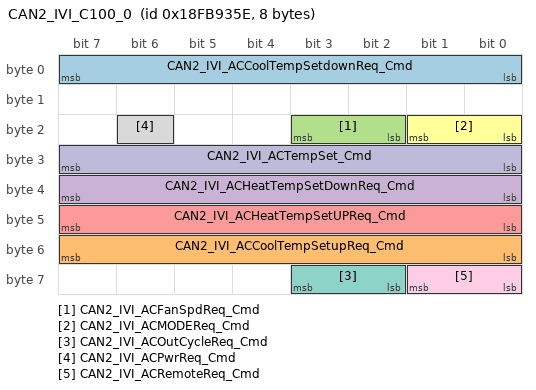
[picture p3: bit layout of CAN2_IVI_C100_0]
      frame CAN2_IVI_C100_0: id 0x18FB935E, frame-length=8, can-addressing-mode=EXTENDED, can-fd-frame-support=false, can-frame-rx-behavior=CAN-20, can-frame-tx-behavior=CAN-20
        pdu CAN2_IVI_C100_0: length=8, minimum-delay=0.0, transmission-mode-true-timing=cyclic-timing=time-period=0.1, unused-bit-pattern=0
          mapping CAN2_SG_IVI_C100_0: i-signal-group=CAN2_SG_IVI_C100_0, start-position=0, transfer-property=PENDING
          signal CAN2_IVI_ACCoolTempSetdownReq_Cmd: start 7, 8 bit, big-endian, i-signal-type=PRIMITIVE, init-value=constant-reference=Init_CAN2_IVI_ACCoolTempSetdownReq_Cmd, base-type=uint8, implementation-data-type=uint8, transfer-property=PENDING
          signal CAN2_IVI_ACCoolTempSetupReq_Cmd: start 48, 8 bit, little-endian, i-signal-type=PRIMITIVE, init-value=constant-reference=Init_CAN2_IVI_ACCoolTempSetupReq_Cmd, base-type=uint8, implementation-data-type=uint8, transfer-property=PENDING
          signal CAN2_IVI_ACFanSpdReq_Cmd: start 18, 2 bit, little-endian, i-signal-type=PRIMITIVE, init-value=constant-reference=Init_CAN2_IVI_ACFanSpdReq_Cmd, base-type=uint8, implementation-data-type=uint8, transfer-property=PENDING
          signal CAN2_IVI_ACHeatTempSetDownReq_Cmd: start 32, 8 bit, little-endian, i-signal-type=PRIMITIVE, init-value=constant-reference=Init_CAN2_IVI_ACHeatTempSetDownReq_Cmd, base-type=uint8, implementation-data-type=uint8, transfer-property=PENDING
          signal CAN2_IVI_ACHeatTempSetUPReq_Cmd: start 40, 8 bit, little-endian, i-signal-type=PRIMITIVE, init-value=constant-reference=Init_CAN2_IVI_ACHeatTempSetUPReq_Cmd, base-type=uint8, implementation-data-type=uint8, transfer-property=PENDING
          signal CAN2_IVI_ACMODEReq_Cmd: start 16, 2 bit, little-endian, i-signal-type=PRIMITIVE, init-value=constant-reference=Init_CAN2_IVI_ACMODEReq_Cmd, base-type=uint8, implementation-data-type=uint8, transfer-property=PENDING
          signal CAN2_IVI_ACOutCycleReq_Cmd: start 58, 2 bit, little-endian, i-signal-type=PRIMITIVE, init-value=constant-reference=Init_CAN2_IVI_ACOutCycleReq_Cmd, base-type=uint8, implementation-data-type=uint8, transfer-property=PENDING
          signal CAN2_IVI_ACPwrReq_Cmd: start 22, 1 bit, little-endian, i-signal-type=PRIMITIVE, init-value=constant-reference=Init_CAN2_IVI_ACPwrReq_Cmd, base-type=uint8, implementation-data-type=uint8, transfer-property=PENDING
          signal CAN2_IVI_ACRemoteReq_Cmd: start 56, 2 bit, little-endian, i-signal-type=PRIMITIVE, init-value=constant-reference=Init_CAN2_IVI_ACRemoteReq_Cmd, base-type=uint8, implementation-data-type=uint8, transfer-property=PENDING
          signal CAN2_IVI_ACTempSet_Cmd: start 24, 8 bit, little-endian, i-signal-type=PRIMITIVE, init-value=constant-reference=Init_CAN2_IVI_ACTempSet_Cmd, base-type=uint8, implementation-data-type=uint8, transfer-property=PENDING
      frame CAN2_NMm_FUSION_TX: id 0x500, frame-length=8, can-addressing-mode=STANDARD, can-fd-frame-support=false, can-frame-rx-behavior=CAN-20, can-frame-tx-behavior=CAN-20
        nm pdu CAN2_NMm_FUSION_TX: length=8, unused-bit-pattern=0
      frame CAN2_NMm_FUSION_RX: id 0x500, frame-length=8, can-addressing-mode=STANDARD, can-fd-frame-support=false, can-frame-rx-behavior=CAN-20, can-frame-tx-behavior=CAN-20
        nm pdu CAN2_NMm_FUSION_RX: length=8, unused-bit-pattern=0
package /CAN2/ConstantSpecification
  183 x constant specification:
    Init_CAN2_ACMODESta: value-spec=0
    Init_CAN2_LBIBatWarn: value-spec=0
    Init_CAN2_LBIPressIndi: value-spec=0
    Init_CAN2_LBISensorFail: value-spec=0
    Init_CAN2_LBIWheelPress: value-spec=0
    Init_CAN2_LBIWheelTemp: value-spec=0
    Init_CAN2_LBIWheelTmpIndi: value-spec=0
    Init_CAN2_LBOBatWarn: value-spec=0
    Init_CAN2_LBOPressIndi: value-spec=0
    Init_CAN2_LBOSensorFail: value-spec=0
    Init_CAN2_LBOWheelPress: value-spec=0
    Init_CAN2_LBOWheelTemp: value-spec=0
    Init_CAN2_LBOWheelTmpIndi: value-spec=0
    Init_CAN2_LFBatWarn: value-spec=0
    Init_CAN2_LFPressIndi: value-spec=0
    Init_CAN2_LFSensorFail: value-spec=0
    Init_CAN2_LFWheelPress: value-spec=0
    Init_CAN2_LFWheelTemp: value-spec=0
    Init_CAN2_LFWheelTmpIndi: value-spec=0
    Init_CAN2_RBIBatWarn: value-spec=0
    Init_CAN2_RBIPressIndi: value-spec=0
    Init_CAN2_RBISensorFail: value-spec=0
    Init_CAN2_RBIWheelPress: value-spec=0
    Init_CAN2_RBIWheelTmpIndi: value-spec=0
    Init_CAN2_RBOBatWarn: value-spec=0
    Init_CAN2_RBOPressIndi: value-spec=0
    Init_CAN2_RBOSensorFail: value-spec=0
    Init_CAN2_RBOWheelPress: value-spec=0
    Init_CAN2_RBOWheelTemp: value-spec=0
    Init_CAN2_RBOWheelTmpIndi: value-spec=0
    Init_CAN2_RFBatWarn: value-spec=0
    Init_CAN2_RFPressIndi: value-spec=0
    Init_CAN2_RFSensorFail: value-spec=0
    Init_CAN2_RFWheelPress: value-spec=0
    Init_CAN2_RFWheelTemp: value-spec=0
    Init_CAN2_RFWheelTmpIndi: value-spec=0
    Init_CAN2_THCM_Faultlv_Sta: value-spec=0
    Init_CAN2_TPMSWarnIndi: value-spec=0
    Init_CAN2_VCUVehAcclLimit: value-spec=0
    Init_CAN2_VCUVehSpdlimit: value-spec=0
    Init_CAN2_ActDriveMode: value-spec=0
    Init_CAN2_CeTraxSysReady: value-spec=0
    Init_CAN2_CreeperSta: value-spec=0
    Init_CAN2_EBrakeTorqLow: value-spec=0
    Init_CAN2_EMotorOverSpd: value-spec=0
    Init_CAN2_EMotorPerformance: value-spec=0
    Init_CAN2_EMotorSpd: value-spec=0
    Init_CAN2_EVECU1MSGCS: value-spec=0
    Init_CAN2_EVECU1MSGCnt: value-spec=0
    Init_CAN2_RecuperHighSta: value-spec=0
    Init_CAN2_TUpASta: value-spec=0
    Init_CAN2_VehActDriveDirect: value-spec=0
    Init_CAN2_WheelSlipdet: value-spec=0
    Init_CAN2_CACPresWarn: value-spec=0
    Init_CAN2_FDC_VCU_VCUDRM_Sta: value-spec=0
    Init_CAN2_SysPowerMode: value-spec=0
    Init_CAN2_IGNKeySta: value-spec=0
    Init_CAN2_VCU_VehicleSpd: value-spec=0
    Init_CAN2_VSPFunc: value-spec=0
    Init_CAN2_EVEHCMSGCS: value-spec=0
    Init_CAN2_EVEHCMSGCnt: value-spec=0
    Init_CAN2_EVSysRls: value-spec=0
    Init_CAN2_ElecSysRdy: value-spec=0
    Init_CAN2_ExtAccLimReq: value-spec=0
    Init_CAN2_ExtDischgReq: value-spec=0
    Init_CAN2_ExtDriveMReq: value-spec=0
    Init_CAN2_ExtWorkshopMReq: value-spec=0
    Init_CAN2_RecuperLimOrReq: value-spec=0
    Init_CAN2_FDC_BCM_BSD_Buzzer_Cmd: value-spec=0
    Init_CAN2_FDC_BCM_Brake_Cmd: value-spec=0
    Init_CAN2_FDC_BCM_CallBell_Cmd: value-spec=0
    Init_CAN2_FDC_BCM_DVRSignalL_Cmd: value-spec=0
    Init_CAN2_FDC_BCM_DVRSignalR_Cmd: value-spec=0
    Init_CAN2_FDC_BCM_EmExitSW_Sta: value-spec=0
    Init_CAN2_FDC_BCM_EmSV_Cmd: value-spec=0
    Init_CAN2_FDC_BCM_FDCloseSV_Cmd: value-spec=0
    Init_CAN2_FDC_BCM_FDOpenSV_Cmd: value-spec=0
    Init_CAN2_FDC_BCM_FDoor_Sta: value-spec=0
    Init_CAN2_FDC_BCM_FRoomLpSet_Sta: value-spec=0
    Init_CAN2_FDC_BCM_HBeam_Cmd: value-spec=0
    Init_CAN2_FDC_BCM_HazardSW_Sta: value-spec=0
    Init_CAN2_FDC_BCM_HelpIND_Cmd: value-spec=0
    Init_CAN2_FDC_BCM_InnerBuzzerMode_Sta: value-spec=0
    Init_CAN2_FDC_BCM_InnerBuzzer_Cmd: value-spec=0
    Init_CAN2_FDC_BCM_InnerCallBell_Cmd: value-spec=0
    Init_CAN2_FDC_BCM_LBSDR_Cmd: value-spec=0
    Init_CAN2_FDC_BCM_LBSDY_Cmd: value-spec=0
    Init_CAN2_FDC_BCM_LBeam_Cmd: value-spec=0
    Init_CAN2_FDC_BCM_LDRL_Cmd: value-spec=0
    Init_CAN2_FDC_BCM_LTurnLp_Cmd: value-spec=0
    Init_CAN2_FDC_BCM_LTurnSW_Sta: value-spec=0
    Init_CAN2_FDC_BCM_MDCloseSV_Cmd: value-spec=0
    Init_CAN2_FDC_BCM_MDOpenSV_Cmd: value-spec=0
    Init_CAN2_FDC_BCM_MDoor_Sta: value-spec=0
    Init_CAN2_FDC_BCM_MRoomLpSet_Sta: value-spec=0
    Init_CAN2_FDC_BCM_OutDoorOpenSW_Sta: value-spec=0
    Init_CAN2_FDC_BCM_PLamp_Cmd: value-spec=0
    Init_CAN2_FDC_BCM_RBSDR_Cmd: value-spec=0
    Init_CAN2_FDC_BCM_RBSDY_Cmd: value-spec=0
    Init_CAN2_FDC_BCM_RDRL_Cmd: value-spec=0
    Init_CAN2_FDC_BCM_RDoor_Sta: value-spec=0
    Init_CAN2_FDC_BCM_RFLamp_Cmd: value-spec=0
    Init_CAN2_FDC_BCM_RGear_Sta: value-spec=0
    Init_CAN2_FDC_BCM_RRoomLpSet_Sta: value-spec=0
    Init_CAN2_FDC_BCM_RTurnLp_Cmd: value-spec=0
    Init_CAN2_FDC_BCM_RTurnSW_Sta: value-spec=0
    Init_CAN2_FDC_BCM_RoomLpAmbSet_Sta: value-spec=0
    Init_CAN2_FDC_BCM_RoomLpAmb_Cmd: value-spec=0
    Init_CAN2_FDC_BCM_RoomLpSet_Sta: value-spec=0
    Init_CAN2_FDC_BCM_SLTLp_Cmd: value-spec=0
    Init_CAN2_FDC_BCM_SMKL_Cmd: value-spec=0
    Init_CAN2_FDC_BCM_SMKR_Cmd: value-spec=0
    Init_CAN2_FDC_BCM_SRTLp_Cmd: value-spec=0
    Init_CAN2_FDC_BCM_STOPBALL_Cmd: value-spec=0
    Init_CAN2_FDC_BCM_Stop_IND_Cmd: value-spec=0
    Init_CAN2_FDC_BCM_TurnBuzzerEN_Sta: value-spec=0
    Init_CAN2_FDC_BCM_TurnLpPattern_Sta: value-spec=0
    Init_CAN2_FDC_BCM_Washer_Cmd: value-spec=0
    Init_CAN2_FDC_BCM_WiperH_Cmd: value-spec=0
    Init_CAN2_FDC_BCM_WiperL_Cmd: value-spec=0
    Init_CAN2_ABSFullyOper: value-spec=0
    Init_CAN2_ACTempSetSta: value-spec=0
    Init_CAN2_ASC1KneelingInfo: value-spec=0
    Init_CAN2_ASRBrakeCtrlAtc: value-spec=0
    Init_CAN2_ASREngCtrlAtc: value-spec=0
    Init_CAN2_AirPressureRC1: value-spec=0
    Init_CAN2_B2THVRlySta: value-spec=0
    Init_CAN2_B2VBI1BattType: value-spec=0
    Init_CAN2_B2VBI1RateCap: value-spec=0
    Init_CAN2_B2VBI1RateHVolt: value-spec=0
    Init_CAN2_B2VBI1RatePower: value-spec=0
    Init_CAN2_B2VChgMode: value-spec=0
    Init_CAN2_B2VChgSta: value-spec=0
    Init_CAN2_B2VDCChgConnSta: value-spec=0
    Init_CAN2_B2VFaultCode: value-spec=0
    Init_CAN2_B2VPChrgConnSta: value-spec=0
    Init_CAN2_B2VSOC: value-spec=0
    Init_CAN2_B2VSOH: value-spec=0
    Init_CAN2_CACTempWarn: value-spec=0
    Init_CAN2_DACStatus: value-spec=0
    Init_CAN2_DCDC_En_Sta: value-spec=0
    Init_CAN2_EBSAmWarnLampSta: value-spec=0
    Init_CAN2_EBSBrakeSw: value-spec=0
    Init_CAN2_EBSRedWarnLampSta: value-spec=0
    Init_CAN2_ECASAWarmLampSta: value-spec=0
    Init_CAN2_EHPS_ErrLv_Sta: value-spec=0
    Init_CAN2_GearFlashInd: value-spec=0
    Init_CAN2_LVBattLow: value-spec=0
    Init_CAN2_MCUFailGrade: value-spec=0
    Init_CAN2_ParkBrakeSW: value-spec=0
    Init_CAN2_PweLmtInd: value-spec=0
    Init_CAN2_TransReqGear: value-spec=0
    Init_CAN2_VCUWarnInd: value-spec=0
    Init_CAN2_VCUnoPBInd: value-spec=0
    Init_CAN2_VDCBrakeLightReq: value-spec=0
    Init_CAN2_WhlSpeed_FL: value-spec=0
    Init_CAN2_WhlSpeed_FR: value-spec=0
    Init_CAN2_WhlSpeed_RL: value-spec=0
    Init_CAN2_WhlSpeed_RR: value-spec=0
    Init_CAN2_ZFR_CHASSIS_LiningWearFL_Sta: value-spec=0
    Init_CAN2_ZFR_CHASSIS_LiningWearFR_Sta: value-spec=0
    Init_CAN2_ZRR_CHASSIS_LiningWearRL_Sta: value-spec=0
    Init_CAN2_ZRR_CHASSIS_LiningWearRR_Sta: value-spec=0
    Init_CAN2_IVI_ACCoolTempSetdownReq_Cmd: value-spec=0
    Init_CAN2_IVI_ACCoolTempSetupReq_Cmd: value-spec=0
    Init_CAN2_IVI_ACFanSpdReq_Cmd: value-spec=0
    Init_CAN2_IVI_ACHeatTempSetDownReq_Cmd: value-spec=0
    Init_CAN2_IVI_ACHeatTempSetUPReq_Cmd: value-spec=0
    Init_CAN2_IVI_ACMODEReq_Cmd: value-spec=0
    Init_CAN2_IVI_ACOutCycleReq_Cmd: value-spec=0
    Init_CAN2_IVI_ACPwrReq_Cmd: value-spec=0
    Init_CAN2_IVI_ACRemoteReq_Cmd: value-spec=0
    Init_CAN2_IVI_ACTempSet_Cmd: value-spec=0
    Init_CAN2_SG_FD2_C1000_0: value-spec=fields=[Init_CAN2_VCUVehAcclLimit, Init_CAN2_VCUVehSpdlimit]
    Init_CAN2_SG_CGW_FD2_C1000_0: value-spec=fields=[Init_CAN2_ACMODESta, Init_CAN2_LBIBatWarn, Init_CAN2_LBIPressIndi, Init_CAN2_LBISensorFail, Init_CAN2_LBIWheelPress, Init_CAN2_LBIWheelTemp, Init_CAN2_LBIWheelTmpIndi, Init_CAN2_LBOBatWarn, Init_CAN2_LBOPressIndi, Init_CAN2_LBOSensorFail, Init_CAN2_LBOWheelPress, Init_CAN2_LBOWheelTemp, Init_CAN2_LBOWheelTmpIndi, Init_CAN2_LFBatWarn, Init_CAN2_LFPressIndi, Init_CAN2_LFSensorFail, Init_CAN2_LFWheelPress, Init_CAN2_LFWheelTemp, Init_CAN2_LFWheelTmpIndi, Init_CAN2_RBIBatWarn, Init_CAN2_RBIPressIndi, Init_CAN2_RBISensorFail, Init_CAN2_RBIWheelPress, Init_CAN2_RBIWheelTmpIndi, Init_CAN2_RBOBatWarn, Init_CAN2_RBOPressIndi, Init_CAN2_RBOSensorFail, Init_CAN2_RBOWheelPress, Init_CAN2_RBOWheelTemp, Init_CAN2_RBOWheelTmpIndi, Init_CAN2_RFBatWarn, Init_CAN2_RFPressIndi, Init_CAN2_RFSensorFail, Init_CAN2_RFWheelPress, Init_CAN2_RFWheelTemp, Init_CAN2_RFWheelTmpIndi, Init_CAN2_THCM_Faultlv_Sta, Init_CAN2_TPMSWarnIndi]
    Init_CAN2_SG_FD2_C10_0: value-spec=fields=[Init_CAN2_ActDriveMode, Init_CAN2_CeTraxSysReady, Init_CAN2_CreeperSta, Init_CAN2_EBrakeTorqLow, Init_CAN2_EMotorOverSpd, Init_CAN2_EMotorPerformance, Init_CAN2_EMotorSpd, Init_CAN2_EVECU1MSGCS, Init_CAN2_EVECU1MSGCnt, Init_CAN2_RecuperHighSta, Init_CAN2_TUpASta, Init_CAN2_VehActDriveDirect, Init_CAN2_WheelSlipdet]
    Init_CAN2_SG_FD2_C200_0: value-spec=fields=[Init_CAN2_CACPresWarn, Init_CAN2_FDC_VCU_VCUDRM_Sta, Init_CAN2_SysPowerMode]
    Init_CAN2_SG_FD2_C500_0: value-spec=fields=[Init_CAN2_IGNKeySta, Init_CAN2_VCU_VehicleSpd, Init_CAN2_VSPFunc]
    Init_CAN2_SG_FD2_C50_0: value-spec=fields=[Init_CAN2_EVEHCMSGCS, Init_CAN2_EVEHCMSGCnt, Init_CAN2_EVSysRls, Init_CAN2_ElecSysRdy, Init_CAN2_ExtAccLimReq, Init_CAN2_ExtDischgReq, Init_CAN2_ExtDriveMReq, Init_CAN2_ExtWorkshopMReq, Init_CAN2_RecuperLimOrReq]
    Init_CAN2_SG_FD2_CE100_0: value-spec=fields=[Init_CAN2_FDC_BCM_BSD_Buzzer_Cmd, Init_CAN2_FDC_BCM_Brake_Cmd, Init_CAN2_FDC_BCM_CallBell_Cmd, Init_CAN2_FDC_BCM_DVRSignalL_Cmd, Init_CAN2_FDC_BCM_DVRSignalR_Cmd, Init_CAN2_FDC_BCM_EmExitSW_Sta, Init_CAN2_FDC_BCM_EmSV_Cmd, Init_CAN2_FDC_BCM_FDCloseSV_Cmd, Init_CAN2_FDC_BCM_FDOpenSV_Cmd, Init_CAN2_FDC_BCM_FDoor_Sta, Init_CAN2_FDC_BCM_FRoomLpSet_Sta, Init_CAN2_FDC_BCM_HBeam_Cmd, Init_CAN2_FDC_BCM_HazardSW_Sta, Init_CAN2_FDC_BCM_HelpIND_Cmd, Init_CAN2_FDC_BCM_InnerBuzzerMode_Sta, Init_CAN2_FDC_BCM_InnerBuzzer_Cmd, Init_CAN2_FDC_BCM_InnerCallBell_Cmd, Init_CAN2_FDC_BCM_LBSDR_Cmd, Init_CAN2_FDC_BCM_LBSDY_Cmd, Init_CAN2_FDC_BCM_LBeam_Cmd, Init_CAN2_FDC_BCM_LDRL_Cmd, Init_CAN2_FDC_BCM_LTurnLp_Cmd, Init_CAN2_FDC_BCM_LTurnSW_Sta, Init_CAN2_FDC_BCM_MDCloseSV_Cmd, Init_CAN2_FDC_BCM_MDOpenSV_Cmd, Init_CAN2_FDC_BCM_MDoor_Sta, Init_CAN2_FDC_BCM_MRoomLpSet_Sta, Init_CAN2_FDC_BCM_OutDoorOpenSW_Sta, Init_CAN2_FDC_BCM_PLamp_Cmd, Init_CAN2_FDC_BCM_RBSDR_Cmd, Init_CAN2_FDC_BCM_RBSDY_Cmd, Init_CAN2_FDC_BCM_RDRL_Cmd, Init_CAN2_FDC_BCM_RDoor_Sta, Init_CAN2_FDC_BCM_RFLamp_Cmd, Init_CAN2_FDC_BCM_RGear_Sta, Init_CAN2_FDC_BCM_RRoomLpSet_Sta, Init_CAN2_FDC_BCM_RTurnLp_Cmd, Init_CAN2_FDC_BCM_RTurnSW_Sta, Init_CAN2_FDC_BCM_RoomLpAmbSet_Sta, Init_CAN2_FDC_BCM_RoomLpAmb_Cmd, Init_CAN2_FDC_BCM_RoomLpSet_Sta, Init_CAN2_FDC_BCM_SLTLp_Cmd, Init_CAN2_FDC_BCM_SMKL_Cmd, Init_CAN2_FDC_BCM_SMKR_Cmd, Init_CAN2_FDC_BCM_SRTLp_Cmd, Init_CAN2_FDC_BCM_STOPBALL_Cmd, Init_CAN2_FDC_BCM_Stop_IND_Cmd, Init_CAN2_FDC_BCM_TurnBuzzerEN_Sta, Init_CAN2_FDC_BCM_TurnLpPattern_Sta, Init_CAN2_FDC_BCM_Washer_Cmd, Init_CAN2_FDC_BCM_WiperH_Cmd, Init_CAN2_FDC_BCM_WiperL_Cmd]
    Init_CAN2_SG_GW2_C100_0: value-spec=fields=[Init_CAN2_CACTempWarn, Init_CAN2_DACStatus, Init_CAN2_GearFlashInd, Init_CAN2_LVBattLow, Init_CAN2_PweLmtInd, Init_CAN2_VCUWarnInd, Init_CAN2_VCUnoPBInd]
    Init_CAN2_SG_CGW_GW2_C100_0: value-spec=fields=[Init_CAN2_ABSFullyOper, Init_CAN2_ACTempSetSta, Init_CAN2_ASC1KneelingInfo, Init_CAN2_ASRBrakeCtrlAtc, Init_CAN2_ASREngCtrlAtc, Init_CAN2_AirPressureRC1, Init_CAN2_B2THVRlySta, Init_CAN2_B2VBI1BattType, Init_CAN2_B2VBI1RateCap, Init_CAN2_B2VBI1RateHVolt, Init_CAN2_B2VBI1RatePower, Init_CAN2_B2VChgMode, Init_CAN2_B2VChgSta, Init_CAN2_B2VDCChgConnSta, Init_CAN2_B2VFaultCode, Init_CAN2_B2VPChrgConnSta, Init_CAN2_B2VSOC, Init_CAN2_B2VSOH, Init_CAN2_DCDC_En_Sta, Init_CAN2_EBSAmWarnLampSta, Init_CAN2_EBSBrakeSw, Init_CAN2_EBSRedWarnLampSta, Init_CAN2_ECASAWarmLampSta, Init_CAN2_EHPS_ErrLv_Sta, Init_CAN2_MCUFailGrade, Init_CAN2_ParkBrakeSW, Init_CAN2_TransReqGear, Init_CAN2_VDCBrakeLightReq, Init_CAN2_WhlSpeed_FL, Init_CAN2_WhlSpeed_FR, Init_CAN2_WhlSpeed_RL, Init_CAN2_WhlSpeed_RR, Init_CAN2_ZFR_CHASSIS_LiningWearFL_Sta, Init_CAN2_ZFR_CHASSIS_LiningWearFR_Sta, Init_CAN2_ZRR_CHASSIS_LiningWearRL_Sta, Init_CAN2_ZRR_CHASSIS_LiningWearRR_Sta]
    Init_CAN2_SG_IVI_C100_0: value-spec=fields=[Init_CAN2_IVI_ACCoolTempSetdownReq_Cmd, Init_CAN2_IVI_ACCoolTempSetupReq_Cmd, Init_CAN2_IVI_ACFanSpdReq_Cmd, Init_CAN2_IVI_ACHeatTempSetDownReq_Cmd, Init_CAN2_IVI_ACHeatTempSetUPReq_Cmd, Init_CAN2_IVI_ACMODEReq_Cmd, Init_CAN2_IVI_ACOutCycleReq_Cmd, Init_CAN2_IVI_ACPwrReq_Cmd, Init_CAN2_IVI_ACRemoteReq_Cmd, Init_CAN2_IVI_ACTempSet_Cmd]
package /CAN2/ImplementationDataTypes
  10 x impl type, all with category=STRUCTURE:
    DT_CAN2_SG_FD2_C1000_0
      element CAN2_VCUVehAcclLimit: implementation-data-type=uint8
      element CAN2_VCUVehSpdlimit: implementation-data-type=uint8
    DT_CAN2_SG_CGW_FD2_C1000_0
      38 x element, all with category=TYPE_REFERENCE, implementation-data-type=uint8:
        CAN2_ACMODESta
        CAN2_LBIBatWarn
        CAN2_LBIPressIndi
        CAN2_LBISensorFail
        CAN2_LBIWheelPress
        CAN2_LBIWheelTemp
        CAN2_LBIWheelTmpIndi
        CAN2_LBOBatWarn
        CAN2_LBOPressIndi
        CAN2_LBOSensorFail
        CAN2_LBOWheelPress
        CAN2_LBOWheelTemp
        CAN2_LBOWheelTmpIndi
        CAN2_LFBatWarn
        CAN2_LFPressIndi
        CAN2_LFSensorFail
        CAN2_LFWheelPress
        CAN2_LFWheelTemp
        CAN2_LFWheelTmpIndi
        CAN2_RBIBatWarn
        CAN2_RBIPressIndi
        CAN2_RBISensorFail
        CAN2_RBIWheelPress
        CAN2_RBIWheelTmpIndi
        CAN2_RBOBatWarn
        CAN2_RBOPressIndi
        CAN2_RBOSensorFail
        CAN2_RBOWheelPress
        CAN2_RBOWheelTemp
        CAN2_RBOWheelTmpIndi
        CAN2_RFBatWarn
        CAN2_RFPressIndi
        CAN2_RFSensorFail
        CAN2_RFWheelPress
        CAN2_RFWheelTemp
        CAN2_RFWheelTmpIndi
        CAN2_THCM_Faultlv_Sta
        CAN2_TPMSWarnIndi
    DT_CAN2_SG_FD2_C10_0
      13 x element, all with category=TYPE_REFERENCE:
        CAN2_ActDriveMode: implementation-data-type=uint8
        CAN2_CeTraxSysReady: implementation-data-type=uint8
        CAN2_CreeperSta: implementation-data-type=uint8
        CAN2_EBrakeTorqLow: implementation-data-type=uint8
        CAN2_EMotorOverSpd: implementation-data-type=uint8
        CAN2_EMotorPerformance: implementation-data-type=uint16
        CAN2_EMotorSpd: implementation-data-type=uint16
        CAN2_EVECU1MSGCS: implementation-data-type=uint8
        CAN2_EVECU1MSGCnt: implementation-data-type=uint8
        CAN2_RecuperHighSta: implementation-data-type=uint8
        CAN2_TUpASta: implementation-data-type=uint8
        CAN2_VehActDriveDirect: implementation-data-type=uint8
        CAN2_WheelSlipdet: implementation-data-type=uint8
    DT_CAN2_SG_FD2_C200_0
      element CAN2_CACPresWarn: implementation-data-type=uint8
      element CAN2_FDC_VCU_VCUDRM_Sta: implementation-data-type=uint8
      element CAN2_SysPowerMode: implementation-data-type=uint8
    DT_CAN2_SG_FD2_C500_0
      element CAN2_IGNKeySta: implementation-data-type=uint8
      element CAN2_VCU_VehicleSpd: implementation-data-type=uint16
      element CAN2_VSPFunc: implementation-data-type=uint8
    DT_CAN2_SG_FD2_C50_0
      9 x element, all with category=TYPE_REFERENCE, implementation-data-type=uint8:
        CAN2_EVEHCMSGCS
        CAN2_EVEHCMSGCnt
        CAN2_EVSysRls
        CAN2_ElecSysRdy
        CAN2_ExtAccLimReq
        CAN2_ExtDischgReq
        CAN2_ExtDriveMReq
        CAN2_ExtWorkshopMReq
        CAN2_RecuperLimOrReq
    DT_CAN2_SG_FD2_CE100_0
      52 x element, all with category=TYPE_REFERENCE, implementation-data-type=uint8:
        CAN2_FDC_BCM_BSD_Buzzer_Cmd
        CAN2_FDC_BCM_Brake_Cmd
        CAN2_FDC_BCM_CallBell_Cmd
        CAN2_FDC_BCM_DVRSignalL_Cmd
        CAN2_FDC_BCM_DVRSignalR_Cmd
        CAN2_FDC_BCM_EmExitSW_Sta
        CAN2_FDC_BCM_EmSV_Cmd
        CAN2_FDC_BCM_FDCloseSV_Cmd
        CAN2_FDC_BCM_FDOpenSV_Cmd
        CAN2_FDC_BCM_FDoor_Sta
        CAN2_FDC_BCM_FRoomLpSet_Sta
        CAN2_FDC_BCM_HBeam_Cmd
        CAN2_FDC_BCM_HazardSW_Sta
        CAN2_FDC_BCM_HelpIND_Cmd
        CAN2_FDC_BCM_InnerBuzzerMode_Sta
        CAN2_FDC_BCM_InnerBuzzer_Cmd
        CAN2_FDC_BCM_InnerCallBell_Cmd
        CAN2_FDC_BCM_LBSDR_Cmd
        CAN2_FDC_BCM_LBSDY_Cmd
        CAN2_FDC_BCM_LBeam_Cmd
        CAN2_FDC_BCM_LDRL_Cmd
        CAN2_FDC_BCM_LTurnLp_Cmd
        CAN2_FDC_BCM_LTurnSW_Sta
        CAN2_FDC_BCM_MDCloseSV_Cmd
        CAN2_FDC_BCM_MDOpenSV_Cmd
        CAN2_FDC_BCM_MDoor_Sta
        CAN2_FDC_BCM_MRoomLpSet_Sta
        CAN2_FDC_BCM_OutDoorOpenSW_Sta
        CAN2_FDC_BCM_PLamp_Cmd
        CAN2_FDC_BCM_RBSDR_Cmd
        CAN2_FDC_BCM_RBSDY_Cmd
        CAN2_FDC_BCM_RDRL_Cmd
        CAN2_FDC_BCM_RDoor_Sta
        CAN2_FDC_BCM_RFLamp_Cmd
        CAN2_FDC_BCM_RGear_Sta
        CAN2_FDC_BCM_RRoomLpSet_Sta
        CAN2_FDC_BCM_RTurnLp_Cmd
        CAN2_FDC_BCM_RTurnSW_Sta
        CAN2_FDC_BCM_RoomLpAmbSet_Sta
        CAN2_FDC_BCM_RoomLpAmb_Cmd
        CAN2_FDC_BCM_RoomLpSet_Sta
        CAN2_FDC_BCM_SLTLp_Cmd
        CAN2_FDC_BCM_SMKL_Cmd
        CAN2_FDC_BCM_SMKR_Cmd
        CAN2_FDC_BCM_SRTLp_Cmd
        CAN2_FDC_BCM_STOPBALL_Cmd
        CAN2_FDC_BCM_Stop_IND_Cmd
        CAN2_FDC_BCM_TurnBuzzerEN_Sta
        CAN2_FDC_BCM_TurnLpPattern_Sta
        CAN2_FDC_BCM_Washer_Cmd
        CAN2_FDC_BCM_WiperH_Cmd
        CAN2_FDC_BCM_WiperL_Cmd
    DT_CAN2_SG_GW2_C100_0
      7 x element, all with category=TYPE_REFERENCE, implementation-data-type=uint8:
        CAN2_CACTempWarn
        CAN2_DACStatus
        CAN2_GearFlashInd
        CAN2_LVBattLow
        CAN2_PweLmtInd
        CAN2_VCUWarnInd
        CAN2_VCUnoPBInd
    DT_CAN2_SG_CGW_GW2_C100_0
      36 x element, all with category=TYPE_REFERENCE:
        CAN2_ABSFullyOper: implementation-data-type=uint8
        CAN2_ACTempSetSta: implementation-data-type=uint8
        CAN2_ASC1KneelingInfo: implementation-data-type=uint8
        CAN2_ASRBrakeCtrlAtc: implementation-data-type=uint8
        CAN2_ASREngCtrlAtc: implementation-data-type=uint8
        CAN2_AirPressureRC1: implementation-data-type=uint8
        CAN2_B2THVRlySta: implementation-data-type=uint8
        CAN2_B2VBI1BattType: implementation-data-type=uint8
        CAN2_B2VBI1RateCap: implementation-data-type=uint16
        CAN2_B2VBI1RateHVolt: implementation-data-type=uint16
        CAN2_B2VBI1RatePower: implementation-data-type=uint16
        CAN2_B2VChgMode: implementation-data-type=uint8
        CAN2_B2VChgSta: implementation-data-type=uint8
        CAN2_B2VDCChgConnSta: implementation-data-type=uint8
        CAN2_B2VFaultCode: implementation-data-type=uint8
        CAN2_B2VPChrgConnSta: implementation-data-type=uint8
        CAN2_B2VSOC: implementation-data-type=uint8
        CAN2_B2VSOH: implementation-data-type=uint8
        CAN2_DCDC_En_Sta: implementation-data-type=uint8
        CAN2_EBSAmWarnLampSta: implementation-data-type=uint8
        CAN2_EBSBrakeSw: implementation-data-type=uint8
        CAN2_EBSRedWarnLampSta: implementation-data-type=uint8
        CAN2_ECASAWarmLampSta: implementation-data-type=uint8
        CAN2_EHPS_ErrLv_Sta: implementation-data-type=uint8
        CAN2_MCUFailGrade: implementation-data-type=uint8
        CAN2_ParkBrakeSW: implementation-data-type=uint8
        CAN2_TransReqGear: implementation-data-type=uint8
        CAN2_VDCBrakeLightReq: implementation-data-type=uint8
        CAN2_WhlSpeed_FL: implementation-data-type=uint16
        CAN2_WhlSpeed_FR: implementation-data-type=uint16
        CAN2_WhlSpeed_RL: implementation-data-type=uint16
        CAN2_WhlSpeed_RR: implementation-data-type=uint16
        CAN2_ZFR_CHASSIS_LiningWearFL_Sta: implementation-data-type=uint8
        CAN2_ZFR_CHASSIS_LiningWearFR_Sta: implementation-data-type=uint8
        CAN2_ZRR_CHASSIS_LiningWearRL_Sta: implementation-data-type=uint8
        CAN2_ZRR_CHASSIS_LiningWearRR_Sta: implementation-data-type=uint8
    DT_CAN2_SG_IVI_C100_0
      10 x element, all with category=TYPE_REFERENCE, implementation-data-type=uint8:
        CAN2_IVI_ACCoolTempSetdownReq_Cmd
        CAN2_IVI_ACCoolTempSetupReq_Cmd
        CAN2_IVI_ACFanSpdReq_Cmd
        CAN2_IVI_ACHeatTempSetDownReq_Cmd
        CAN2_IVI_ACHeatTempSetUPReq_Cmd
        CAN2_IVI_ACMODEReq_Cmd
        CAN2_IVI_ACOutCycleReq_Cmd
        CAN2_IVI_ACPwrReq_Cmd
        CAN2_IVI_ACRemoteReq_Cmd
        CAN2_IVI_ACTempSet_Cmd
